/*
 * The MIT License (MIT)
 *
 * Copyright (c) 2015-2019 Erik Moqvist
 *
 * Permission is hereby granted, free of charge, to any person obtaining a copy
 * of this software and associated documentation files (the "Software"), to deal
 * in the Software without restriction, including without limitation the rights
 * to use, copy, modify, merge, publish, distribute, sublicense, and/or sell
 * copies of the Software, and to permit persons to whom the Software is
 * furnished to do so, subject to the following conditions:
 *
 * The above copyright notice and this permission notice shall be included in all
 * copies or substantial portions of the Software.
 *
 * THE SOFTWARE IS PROVIDED "AS IS", WITHOUT WARRANTY OF ANY KIND, EXPRESS OR
 * IMPLIED, INCLUDING BUT NOT LIMITED TO THE WARRANTIES OF MERCHANTABILITY,
 * FITNESS FOR A PARTICULAR PURPOSE AND NONINFRINGEMENT. IN NO EVENT SHALL THE
 * AUTHORS OR COPYRIGHT HOLDERS BE LIABLE FOR ANY CLAIM, DAMAGES OR OTHER
 * LIABILITY, WHETHER IN AN ACTION OF CONTRACT, TORT OR OTHERWISE, ARISING FROM,
 * OUT OF OR IN CONNECTION WITH THE SOFTWARE OR THE USE OR OTHER DEALINGS IN THE
 * SOFTWARE.
 */

VERSION ""

NS_ :

BS_:

BU_: UnusedNode

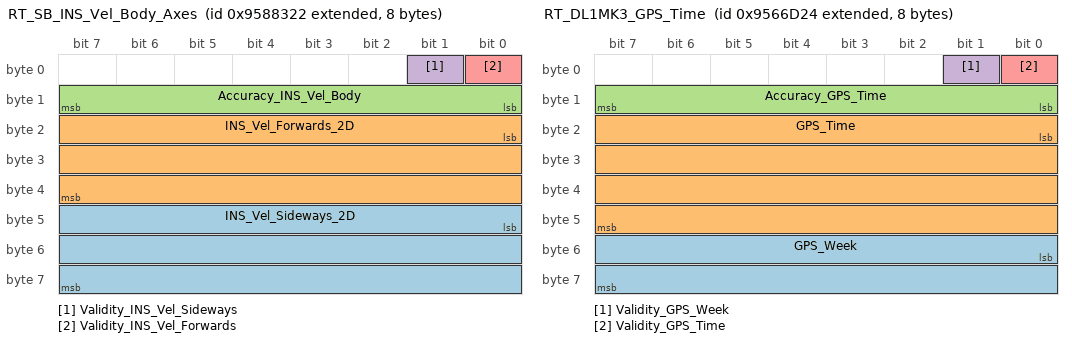
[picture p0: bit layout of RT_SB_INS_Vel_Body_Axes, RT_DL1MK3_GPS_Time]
BO_ 2304279330 RT_SB_INS_Vel_Body_Axes: 8 Vector__XXX
 SG_ INS_Vel_Sideways_2D : 40|24@1- (0.0001,0) [-838|838] "m/s" Vector__XXX
 SG_ INS_Vel_Forwards_2D : 16|24@1- (0.0001,0) [-838|838] "m/s" Vector__XXX
 SG_ Accuracy_INS_Vel_Body : 8|8@1+ (1,0) [0|255] "" Vector__XXX
 SG_ Validity_INS_Vel_Sideways : 1|1@1+ (1,0) [0|1] "" Vector__XXX
 SG_ Validity_INS_Vel_Forwards : 0|1@1+ (1,0) [0|1] "" Vector__XXX

BO_ 2303360036 RT_DL1MK3_Speed: 8 Vector__XXX
 SG_ Speed : 16|32@1- (1e-05,0) [-20000|20000] "m/s" Vector__XXX
 SG_ Accuracy_Speed : 8|8@1+ (1,0) [0|255] "" Vector__XXX
 SG_ Validity_Speed : 0|1@1+ (1,0) [0|0] "" Vector__XXX

BO_ 2304142628 RT_DL1MK3_GPS_Time: 8 Vector__XXX
 SG_ GPS_Week : 48|16@1+ (1,0) [0|65535] "" Vector__XXX
 SG_ GPS_Time : 16|32@1+ (0.001,0) [0|604800] "s" Vector__XXX
 SG_ Accuracy_GPS_Time : 8|8@1+ (1,0) [0|255] "" Vector__XXX
 SG_ Validity_GPS_Week : 1|1@1+ (1,0) [0|1] "" Vector__XXX
 SG_ Validity_GPS_Time : 0|1@1+ (1,0) [0|1] "" Vector__XXX

BO_ 2304143140 RT_DL1MK3_GPS_Pos_LLH_2: 8 Vector__XXX
 SG_ GPS_Pos_LLH_Altitude : 32|32@1- (0.001,0) [-1000|100000] "m" Vector__XXX
 SG_ GPS_Pos_LLH_Longitude : 0|32@1- (1e-07,0) [-180|180] "degrees" Vector__XXX

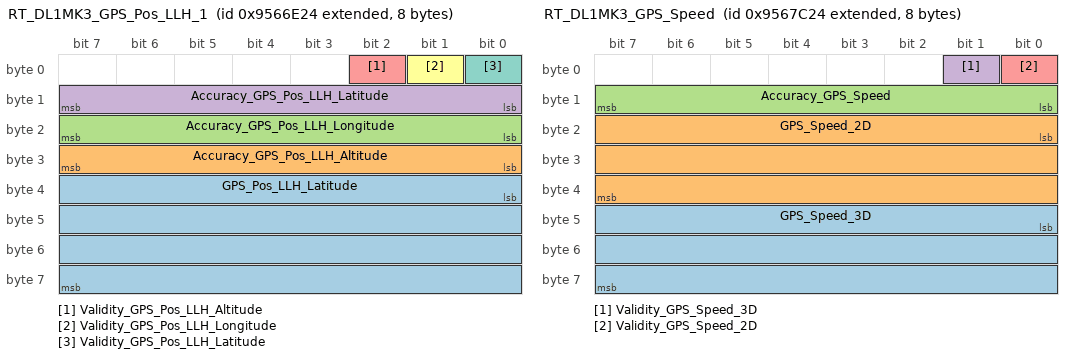
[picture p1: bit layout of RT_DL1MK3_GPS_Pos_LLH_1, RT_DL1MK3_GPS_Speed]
BO_ 2304142884 RT_DL1MK3_GPS_Pos_LLH_1: 8 Vector__XXX
 SG_ GPS_Pos_LLH_Latitude : 32|32@1- (1e-07,0) [-90|90] "degrees" Vector__XXX
 SG_ Accuracy_GPS_Pos_LLH_Altitude : 24|8@1+ (1,0) [0|255] "" Vector__XXX
 SG_ Accuracy_GPS_Pos_LLH_Longitude : 16|8@1+ (1,0) [0|255] "" Vector__XXX
 SG_ Accuracy_GPS_Pos_LLH_Latitude : 8|8@1+ (1,0) [0|255] "" Vector__XXX
 SG_ Validity_GPS_Pos_LLH_Altitude : 2|1@1+ (1,0) [0|1] "" Vector__XXX
 SG_ Validity_GPS_Pos_LLH_Longitude : 1|1@1+ (1,0) [0|1] "" Vector__XXX
 SG_ Validity_GPS_Pos_LLH_Latitude : 0|1@1+ (1,0) [0|1] "" Vector__XXX

BO_ 2304146468 RT_DL1MK3_GPS_Speed: 8 Vector__XXX
 SG_ GPS_Speed_3D : 40|24@1+ (0.0001,0) [0|1675] "m/s" Vector__XXX
 SG_ GPS_Speed_2D : 16|24@1+ (0.0001,0) [0|1675] "m/s" Vector__XXX
 SG_ Accuracy_GPS_Speed : 8|8@1+ (1,0) [0|255] "" Vector__XXX
 SG_ Validity_GPS_Speed_3D : 1|1@1+ (1,0) [0|1] "" Vector__XXX
 SG_ Validity_GPS_Speed_2D : 0|1@1+ (1,0) [0|1] "" Vector__XXX

BO_ 2304471845 RT_IRTemp_Temp_7: 2 Vector__XXX
 SG_ IR_Temperature_7 : 0|16@1- (0.1,0) [0|0] "" Vector__XXX

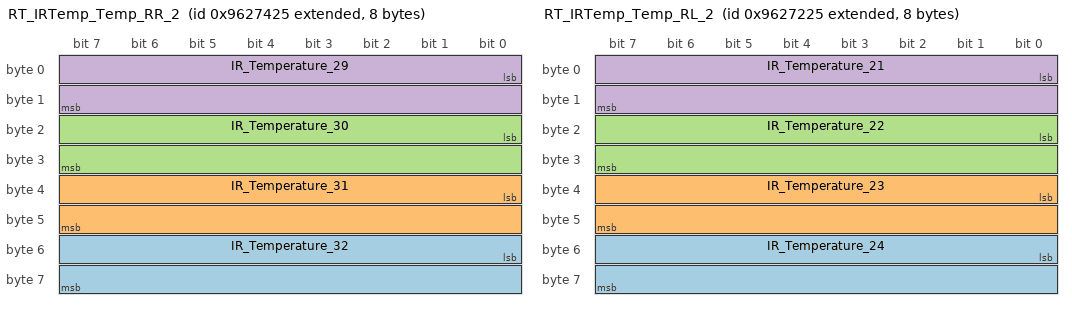
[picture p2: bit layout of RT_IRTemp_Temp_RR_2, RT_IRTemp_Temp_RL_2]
BO_ 2304930853 RT_IRTemp_Temp_RR_2: 8 Vector__XXX
 SG_ IR_Temperature_32 : 48|16@1- (0.1,0) [0|0] "" Vector__XXX
 SG_ IR_Temperature_31 : 32|16@1- (0.1,0) [0|0] "" Vector__XXX
 SG_ IR_Temperature_30 : 16|16@1- (0.1,0) [0|0] "" Vector__XXX
 SG_ IR_Temperature_29 : 0|16@1- (0.1,0) [0|0] "" Vector__XXX

BO_ 2304930341 RT_IRTemp_Temp_RL_2: 8 Vector__XXX
 SG_ IR_Temperature_24 : 48|16@1- (0.1,0) [0|0] "" Vector__XXX
 SG_ IR_Temperature_23 : 32|16@1- (0.1,0) [0|0] "" Vector__XXX
 SG_ IR_Temperature_22 : 16|16@1- (0.1,0) [0|0] "" Vector__XXX
 SG_ IR_Temperature_21 : 0|16@1- (0.1,0) [0|0] "" Vector__XXX

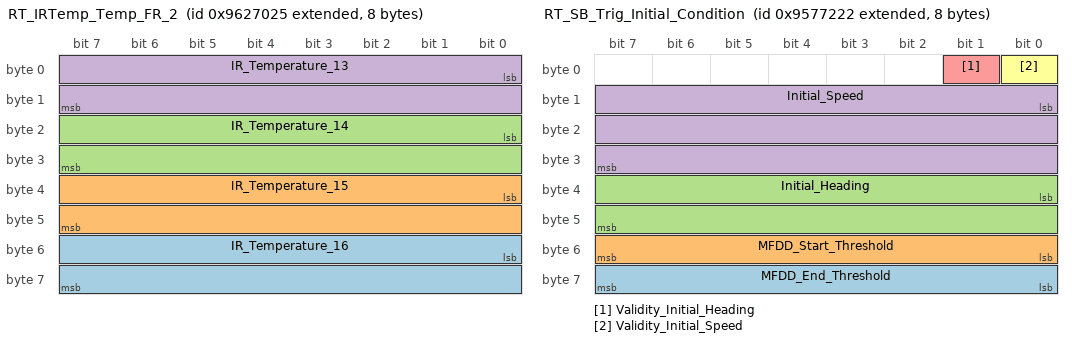
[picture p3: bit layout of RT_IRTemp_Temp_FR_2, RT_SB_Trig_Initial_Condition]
BO_ 2304929829 RT_IRTemp_Temp_FR_2: 8 Vector__XXX
 SG_ IR_Temperature_16 : 48|16@1- (0.1,0) [0|0] "" Vector__XXX
 SG_ IR_Temperature_15 : 32|16@1- (0.1,0) [0|0] "" Vector__XXX
 SG_ IR_Temperature_14 : 16|16@1- (0.1,0) [0|0] "" Vector__XXX
 SG_ IR_Temperature_13 : 0|16@1- (0.1,0) [0|0] "" Vector__XXX

BO_ 2304929317 RT_IRTemp_Temp_FL_2: 8 Vector__XXX
 SG_ IR_Temperature_8 : 48|16@1- (0.1,0) [0|0] "" Vector__XXX
 SG_ IR_Temperature_7 : 32|16@1- (0.1,0) [0|0] "" Vector__XXX
 SG_ IR_Temperature_6 : 16|16@1- (0.1,0) [0|0] "" Vector__XXX
 SG_ IR_Temperature_5 : 0|16@1- (0.1,0) [0|0] "" Vector__XXX

BO_ 2304930597 RT_IRTemp_Temp_RR_1: 8 Vector__XXX
 SG_ IR_Temperature_28 : 48|16@1- (0.1,0) [0|0] "" Vector__XXX
 SG_ IR_Temperature_27 : 32|16@1- (0.1,0) [0|0] "" Vector__XXX
 SG_ IR_Temperature_26 : 16|16@1- (0.1,0) [0|0] "" Vector__XXX
 SG_ IR_Temperature_25 : 0|16@1- (0.1,0) [0|0] "" Vector__XXX

BO_ 2304930085 RT_IRTemp_Temp_RL_1: 8 Vector__XXX
 SG_ IR_Temperature_20 : 48|16@1- (0.1,0) [0|0] "" Vector__XXX
 SG_ IR_Temperature_19 : 32|16@1- (0.1,0) [0|0] "" Vector__XXX
 SG_ IR_Temperature_18 : 16|16@1- (0.1,0) [0|0] "" Vector__XXX
 SG_ IR_Temperature_17 : 0|16@1- (0.1,0) [0|0] "" Vector__XXX

BO_ 2304929573 RT_IRTemp_Temp_FR_1: 8 Vector__XXX
 SG_ IR_Temperature_12 : 48|16@1- (0.1,0) [0|0] "" Vector__XXX
 SG_ IR_Temperature_11 : 32|16@1- (0.1,0) [0|0] "" Vector__XXX
 SG_ IR_Temperature_10 : 16|16@1- (0.1,0) [0|0] "" Vector__XXX
 SG_ IR_Temperature_9 : 0|16@1- (0.1,0) [0|0] "" Vector__XXX

BO_ 2304929061 RT_IRTemp_Temp_FL_1: 8 Vector__XXX
 SG_ IR_Temperature_4 : 48|16@1- (0.1,0) [0|0] "" Vector__XXX
 SG_ IR_Temperature_3 : 32|16@1- (0.1,0) [0|0] "" Vector__XXX
 SG_ IR_Temperature_2 : 16|16@1- (0.1,0) [0|0] "" Vector__XXX
 SG_ IR_Temperature_1 : 0|16@1- (0.1,0) [0|0] "" Vector__XXX

BO_ 2304478245 RT_IRTemp_Temp_32: 2 Vector__XXX
 SG_ IR_Temperature_32 : 0|16@1- (0.1,0) [0|0] "" Vector__XXX

BO_ 2304477989 RT_IRTemp_Temp_31: 2 Vector__XXX
 SG_ IR_Temperature_31 : 0|16@1- (0.1,0) [0|0] "" Vector__XXX

BO_ 2304477733 RT_IRTemp_Temp_30: 2 Vector__XXX
 SG_ IR_Temperature_30 : 0|16@1- (0.1,0) [0|0] "" Vector__XXX

BO_ 2304477477 RT_IRTemp_Temp_29: 2 Vector__XXX
 SG_ IR_Temperature_29 : 0|16@1- (0.1,0) [0|0] "" Vector__XXX

BO_ 2304477221 RT_IRTemp_Temp_28: 2 Vector__XXX
 SG_ IR_Temperature_28 : 0|16@1- (0.1,0) [0|0] "" Vector__XXX

BO_ 2304476965 RT_IRTemp_Temp_27: 2 Vector__XXX
 SG_ IR_Temperature_27 : 0|16@1- (0.1,0) [0|0] "" Vector__XXX

BO_ 2304476709 RT_IRTemp_Temp_26: 2 Vector__XXX
 SG_ IR_Temperature_26 : 0|16@1- (0.1,0) [0|0] "" Vector__XXX

BO_ 2304476453 RT_IRTemp_Temp_25: 2 Vector__XXX
 SG_ IR_Temperature_25 : 0|16@1- (0.1,0) [0|0] "" Vector__XXX

BO_ 2304476197 RT_IRTemp_Temp_24: 2 Vector__XXX
 SG_ IR_Temperature_24 : 0|16@1- (0.1,0) [0|0] "" Vector__XXX

BO_ 2304475685 RT_IRTemp_Temp_22: 2 Vector__XXX
 SG_ IR_Temperature_22 : 0|16@1- (0.1,0) [0|0] "" Vector__XXX

BO_ 2304475941 RT_IRTemp_Temp_23: 2 Vector__XXX
 SG_ IR_Temperature_23 : 0|16@1- (0.1,0) [0|0] "" Vector__XXX

BO_ 2304475429 RT_IRTemp_Temp_21: 2 Vector__XXX
 SG_ IR_Temperature_21 : 0|16@1- (0.1,0) [0|0] "" Vector__XXX

BO_ 2304475173 RT_IRTemp_Temp_20: 2 Vector__XXX
 SG_ IR_Temperature_20 : 0|16@1- (0.1,0) [0|0] "" Vector__XXX

BO_ 2304474917 RT_IRTemp_Temp_19: 2 Vector__XXX
 SG_ IR_Temperature_19 : 0|16@1- (0.1,0) [0|0] "" Vector__XXX

BO_ 2304474661 RT_IRTemp_Temp_18: 2 Vector__XXX
 SG_ IR_Temperature_18 : 0|16@1- (0.1,0) [0|0] "" Vector__XXX

BO_ 2304474149 RT_IRTemp_Temp_16: 2 Vector__XXX
 SG_ IR_Temperature_16 : 0|16@1- (0.1,0) [0|0] "" Vector__XXX

BO_ 2304473893 RT_IRTemp_Temp_15: 2 Vector__XXX
 SG_ IR_Temperature_15 : 0|16@1- (0.1,0) [0|0] "" Vector__XXX

BO_ 2304473637 RT_IRTemp_Temp_14: 2 Vector__XXX
 SG_ IR_Temperature_14 : 0|16@1- (0.1,0) [0|0] "" Vector__XXX

BO_ 2304473381 RT_IRTemp_Temp_13: 2 Vector__XXX
 SG_ IR_Temperature_13 : 0|16@1- (0.1,0) [0|0] "" Vector__XXX

BO_ 2304473125 RT_IRTemp_Temp_12: 2 Vector__XXX
 SG_ IR_Temperature_12 : 0|16@1- (0.1,0) [0|0] "" Vector__XXX

BO_ 2304472869 RT_IRTemp_Temp_11: 2 Vector__XXX
 SG_ IR_Temperature_11 : 0|16@1- (0.1,0) [0|0] "" Vector__XXX

BO_ 2304472613 RT_IRTemp_Temp_10: 2 Vector__XXX
 SG_ IR_Temperature_10 : 0|16@1- (0.1,0) [0|0] "" Vector__XXX

BO_ 2304472101 RT_IRTemp_Temp_8: 2 Vector__XXX
 SG_ IR_Temperature_8 : 0|16@1- (0.1,0) [0|0] "" Vector__XXX

BO_ 2304472357 RT_IRTemp_Temp_9: 2 Vector__XXX
 SG_ IR_Temperature_9 : 0|16@1- (0.1,0) [0|0] "" Vector__XXX

BO_ 2304474405 RT_IRTemp_Temp_17: 2 Vector__XXX
 SG_ IR_Temperature_17 : 0|16@1- (0.1,0) [0|0] "" Vector__XXX

BO_ 2304471589 RT_IRTemp_Temp_6: 2 Vector__XXX
 SG_ IR_Temperature_6 : 0|16@1- (0.1,0) [0|0] "" Vector__XXX

BO_ 2304471333 RT_IRTemp_Temp_5: 2 Vector__XXX
 SG_ IR_Temperature_5 : 0|16@1- (0.1,0) [0|0] "" Vector__XXX

BO_ 2304471077 RT_IRTemp_Temp_4: 2 Vector__XXX
 SG_ IR_Temperature_4 : 0|16@1- (0.1,0) [0|0] "" Vector__XXX

BO_ 2304470821 RT_IRTemp_Temp_3: 2 Vector__XXX
 SG_ IR_Temperature_3 : 0|16@1- (0.1,0) [0|0] "" Vector__XXX

BO_ 2304470565 RT_IRTemp_Temp_2: 2 Vector__XXX
 SG_ IR_Temperature_2 : 0|16@1- (0.1,0) [0|0] "" Vector__XXX

BO_ 2304470309 RT_IRTemp_Temp_1: 2 Vector__XXX
 SG_ IR_Temperature_1 : 0|16@1- (0.1,0) [0|0] "" Vector__XXX

BO_ 2304209698 RT_SB_Trig_Final_Condition: 8 Vector__XXX
 SG_ Final_Speed : 8|24@1+ (0.0001,0) [0|1675] "m/s" Vector__XXX
 SG_ Validity_Final_Speed : 0|1@1+ (1,0) [0|1] "" Vector__XXX

BO_ 2304209442 RT_SB_Trig_Initial_Condition: 8 Vector__XXX
 SG_ MFDD_End_Threshold : 56|8@1+ (1,0) [0|100] "%" Vector__XXX
 SG_ MFDD_Start_Threshold : 48|8@1+ (1,0) [0|100] "%" Vector__XXX
 SG_ Initial_Heading : 32|16@1- (0.01,0) [-180|180] "degrees" Vector__XXX
 SG_ Initial_Speed : 8|24@1+ (0.0001,0) [0|1675] "m/s" Vector__XXX
 SG_ Validity_Initial_Heading : 1|1@1+ (1,0) [0|1] "" Vector__XXX
 SG_ Validity_Initial_Speed : 0|1@1+ (1,0) [0|1] "" Vector__XXX

BO_ 2304209186 RT_SB_Trig_Direct_Dist: 8 Vector__XXX
 SG_ Path_Distance_2D : 32|32@1+ (0.001,0) [0|4294967] "m" Vector__XXX
 SG_ Direct_Distance : 0|32@1+ (0.001,0) [0|4294967] "m" Vector__XXX

BO_ 2304208930 RT_SB_Trig_Forward_Dist: 8 Vector__XXX
 SG_ Deviation_Distance : 32|32@1- (0.001,0) [-2147483.648|2147483.647] "m" Vector__XXX
 SG_ Forward_Distance : 0|32@1- (0.001,0) [-2147483.648|2147483.647] "m" Vector__XXX

BO_ 2304208674 RT_SB_Trig_Path_Dist: 8 Vector__XXX
 SG_ Path_Distance_3D : 0|32@1+ (0.001,0) [0|4294967] "m" Vector__XXX

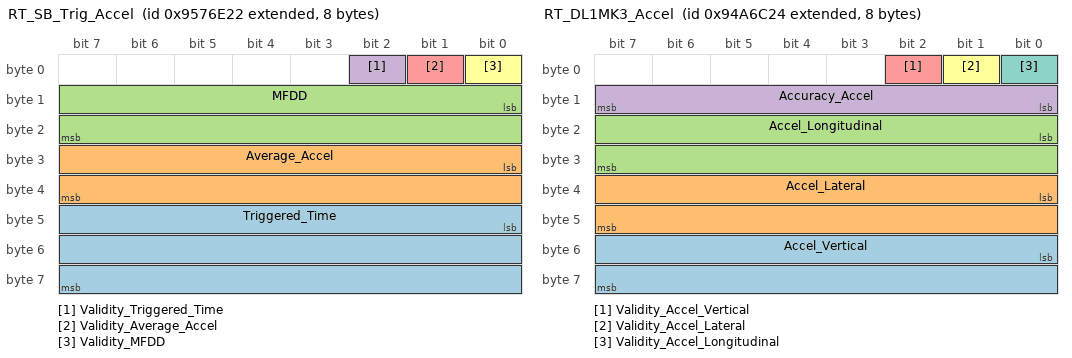
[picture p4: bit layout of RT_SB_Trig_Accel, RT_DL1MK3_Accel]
BO_ 2304208418 RT_SB_Trig_Accel: 8 Vector__XXX
 SG_ Triggered_Time : 40|24@1+ (0.01,0) [0|167772] "s" Vector__XXX
 SG_ Average_Accel : 24|16@1- (0.001,0) [-65|65] "g" Vector__XXX
 SG_ MFDD : 8|16@1- (0.001,0) [-65|65] "g" Vector__XXX
 SG_ Validity_Triggered_Time : 2|1@1+ (1,0) [0|0] "" Vector__XXX
 SG_ Validity_Average_Accel : 1|1@1+ (1,0) [0|0] "" Vector__XXX
 SG_ Validity_MFDD : 0|1@1+ (1,0) [0|0] "" Vector__XXX

BO_ 2304800804 RT_DL1MK3_Measure_Time_12: 3 Vector__XXX
 SG_ Measured_Time_12 : 0|24@1+ (1,0) [0|0] "" Vector__XXX

BO_ 2304800548 RT_DL1MK3_Measure_Time_11: 3 Vector__XXX
 SG_ Measured_Time_11 : 0|24@1+ (1,0) [0|0] "" Vector__XXX

BO_ 2304800292 RT_DL1MK3_Measure_Time_10: 3 Vector__XXX
 SG_ Measured_Time_10 : 0|24@1+ (1,0) [0|0] "" Vector__XXX

BO_ 2304800036 RT_DL1MK3_Measure_Time_9: 3 Vector__XXX
 SG_ Measured_Time_9 : 0|24@1+ (1,0) [0|0] "" Vector__XXX

BO_ 2304799780 RT_DL1MK3_Measure_Time_8: 3 Vector__XXX
 SG_ Measured_Time_8 : 0|24@1+ (1,0) [0|0] "" Vector__XXX

BO_ 2304799524 RT_DL1MK3_Measure_Time_7: 3 Vector__XXX
 SG_ Measured_Time_7 : 0|24@1+ (1,0) [0|0] "" Vector__XXX

BO_ 2304799268 RT_DL1MK3_Measure_Time_6: 3 Vector__XXX
 SG_ Measured_Time_6 : 0|24@1+ (1,0) [0|0] "" Vector__XXX

BO_ 2304799012 RT_DL1MK3_Measure_Time_5: 3 Vector__XXX
 SG_ Measured_Time_5 : 0|24@1+ (1,0) [0|0] "" Vector__XXX

BO_ 2304798756 RT_DL1MK3_Measure_Time_4: 3 Vector__XXX
 SG_ Measured_Time_4 : 0|24@1+ (1,0) [0|0] "" Vector__XXX

BO_ 2304798500 RT_DL1MK3_Measure_Time_3: 3 Vector__XXX
 SG_ Measured_Time_3 : 0|24@1+ (1,0) [0|0] "" Vector__XXX

BO_ 2304798244 RT_DL1MK3_Measure_Time_2: 3 Vector__XXX
 SG_ Measured_Time_2 : 0|24@1+ (1,0) [0|0] "" Vector__XXX

BO_ 2304797988 RT_DL1MK3_Measure_Time_1: 3 Vector__XXX
 SG_ Measured_Time_1 : 0|24@1+ (1,0) [0|0] "" Vector__XXX

BO_ 2304735268 RT_DL1MK3_RPM: 2 Vector__XXX
 SG_ RPM : 0|16@1+ (1,0) [0|0] "" Vector__XXX

BO_ 2304735012 RT_DL1MK3_Freq_4: 2 Vector__XXX
 SG_ Frequency_4 : 0|16@1+ (0.1,0) [0|0] "" Vector__XXX

BO_ 2304734756 RT_DL1MK3_Freq_3: 2 Vector__XXX
 SG_ Frequency_3 : 0|16@1+ (0.1,0) [0|0] "" Vector__XXX

BO_ 2304734500 RT_DL1MK3_Freq_2: 2 Vector__XXX
 SG_ Frequency_2 : 0|16@1+ (0.1,0) [0|0] "" Vector__XXX

BO_ 2304864036 RT_DL1MK3_Misc_3: 2 Vector__XXX
 SG_ Misc_3 : 0|16@1+ (0.001,0) [0|0] "" Vector__XXX

BO_ 2304863780 RT_DL1MK3_Misc_2: 2 Vector__XXX
 SG_ Misc_2 : 0|16@1+ (0.001,0) [0|0] "" Vector__XXX

BO_ 2304863524 RT_DL1MK3_Misc_1: 2 Vector__XXX
 SG_ Misc_1 : 0|16@1+ (0.001,0) [0|0] "" Vector__XXX

BO_ 2304674596 RT_DL1MK3_Aux_31: 2 Vector__XXX
 SG_ AUX_31 : 0|16@1+ (0.1,0) [0|0] "" Vector__XXX

BO_ 2304674340 RT_DL1MK3_Aux_30: 2 Vector__XXX
 SG_ AUX_30 : 0|16@1+ (0.1,0) [0|0] "" Vector__XXX

BO_ 2304674084 RT_DL1MK3_Aux_29: 2 Vector__XXX
 SG_ AUX_29 : 0|16@1+ (0.1,0) [0|0] "" Vector__XXX

BO_ 2304673828 RT_DL1MK3_Aux_28: 2 Vector__XXX
 SG_ AUX_28 : 0|16@1+ (0.1,0) [0|0] "" Vector__XXX

BO_ 2304673572 RT_DL1MK3_Aux_27: 2 Vector__XXX
 SG_ AUX_27 : 0|16@1+ (0.1,0) [0|0] "" Vector__XXX

BO_ 2304673316 RT_DL1MK3_Aux_26: 2 Vector__XXX
 SG_ AUX_26 : 0|16@1+ (0.1,0) [0|0] "" Vector__XXX

BO_ 2304673060 RT_DL1MK3_Aux_25: 2 Vector__XXX
 SG_ AUX_25 : 0|16@1+ (0.1,0) [0|0] "" Vector__XXX

BO_ 2304672804 RT_DL1MK3_Aux_24: 2 Vector__XXX
 SG_ AUX_24 : 0|16@1+ (0.1,0) [0|0] "" Vector__XXX

BO_ 2304672548 RT_DL1MK3_Aux_23: 2 Vector__XXX
 SG_ AUX_23 : 0|16@1+ (0.1,0) [0|0] "" Vector__XXX

BO_ 2304672292 RT_DL1MK3_Aux_22: 2 Vector__XXX
 SG_ AUX_22 : 0|16@1+ (10,0) [0|0] "" Vector__XXX

BO_ 2304672036 RT_DL1MK3_Aux_21: 2 Vector__XXX
 SG_ AUX_21 : 0|16@1+ (0.1,0) [0|0] "" Vector__XXX

BO_ 2304671780 RT_DL1MK3_Aux_20: 2 Vector__XXX
 SG_ AUX_20 : 0|16@1+ (0.1,0) [0|0] "" Vector__XXX

BO_ 2304671524 RT_DL1MK3_Aux_19: 2 Vector__XXX
 SG_ AUX_19 : 0|16@1+ (0.1,0) [0|0] "" Vector__XXX

BO_ 2304671268 RT_DL1MK3_Aux_18: 2 Vector__XXX
 SG_ AUX_18 : 0|16@1+ (0.1,0) [0|0] "" Vector__XXX

BO_ 2304671012 RT_DL1MK3_Aux_17: 2 Vector__XXX
 SG_ AUX_17 : 0|16@1+ (0.1,0) [0|0] "" Vector__XXX

BO_ 2304670756 RT_DL1MK3_Aux_16: 2 Vector__XXX
 SG_ AUX_16 : 0|16@1+ (0.1,0) [0|0] "" Vector__XXX

BO_ 2304670500 RT_DL1MK3_Aux_15: 2 Vector__XXX
 SG_ AUX_15 : 0|16@1+ (0.1,0) [0|0] "" Vector__XXX

BO_ 2304670244 RT_DL1MK3_Aux_14: 2 Vector__XXX
 SG_ AUX_14 : 0|16@1+ (0.1,0) [0|0] "" Vector__XXX

BO_ 2304669988 RT_DL1MK3_Aux_13: 2 Vector__XXX
 SG_ AUX_13 : 0|16@1+ (0.1,0) [0|0] "" Vector__XXX

BO_ 2304669732 RT_DL1MK3_Aux_12: 2 Vector__XXX
 SG_ AUX_12 : 0|16@1+ (0.1,0) [0|0] "" Vector__XXX

BO_ 2304669476 RT_DL1MK3_Aux_11: 2 Vector__XXX
 SG_ AUX_11 : 0|16@1+ (0.1,0) [0|0] "" Vector__XXX

BO_ 2304668964 RT_DL1MK3_Aux_9: 2 Vector__XXX
 SG_ AUX_9 : 0|16@1+ (0.1,0) [0|0] "" Vector__XXX

BO_ 2304669220 RT_DL1MK3_Aux_10: 2 Vector__XXX
 SG_ AUX_10 : 0|16@1+ (0.1,0) [0|0] "" Vector__XXX

BO_ 2304668708 RT_DL1MK3_Aux_8: 2 Vector__XXX
 SG_ AUX_8 : 0|16@1+ (0.1,0) [0|0] "" Vector__XXX

BO_ 2304668452 RT_DL1MK3_Aux_7: 2 Vector__XXX
 SG_ AUX_7 : 0|16@1+ (0.1,0) [0|0] "" Vector__XXX

BO_ 2304668196 RT_DL1MK3_Aux_6: 2 Vector__XXX
 SG_ AUX_6 : 0|16@1+ (0.1,0) [0|0] "" Vector__XXX

BO_ 2304667940 RT_DL1MK3_Aux_5: 2 Vector__XXX
 SG_ AUX_5 : 0|16@1+ (0.1,0) [0|0] "" Vector__XXX

BO_ 2304667684 RT_DL1MK3_Aux_4: 2 Vector__XXX
 SG_ AUX_4 : 0|16@1+ (0.1,0) [0|0] "" Vector__XXX

BO_ 2304667428 RT_DL1MK3_Aux_3: 2 Vector__XXX
 SG_ AUX_3 : 0|16@1+ (0.1,0) [0|0] "" Vector__XXX

BO_ 2304667172 RT_DL1MK3_Aux_2: 2 Vector__XXX
 SG_ AUX_2 : 0|16@1+ (0.1,0) [0|0] "" Vector__XXX

BO_ 2304666916 RT_DL1MK3_Aux_1: 2 Vector__XXX
 SG_ AUX_1 : 0|16@1+ (0.1,0) [0|0] "" Vector__XXX

BO_ 2304405796 RT_DL1MK3_Pressure_5: 3 Vector__XXX
 SG_ Pressure_5 : 0|24@1+ (0.1,0) [0|0] "" Vector__XXX

BO_ 2304405540 RT_DL1MK3_Pressure_4: 3 Vector__XXX
 SG_ Pressure_4 : 0|24@1+ (0.1,0) [0|0] "" Vector__XXX

BO_ 2304405284 RT_DL1MK3_Pressure_3: 3 Vector__XXX
 SG_ Pressure_3 : 0|24@1+ (0.1,0) [0|0] "" Vector__XXX

BO_ 2304405028 RT_DL1MK3_Pressure_2: 3 Vector__XXX
 SG_ Pressure_2 : 0|24@1+ (0.1,0) [0|0] "" Vector__XXX

BO_ 2304404772 RT_DL1MK3_Pressure_1: 3 Vector__XXX
 SG_ Pressure_1 : 0|24@1+ (0.1,0) [0|0] "" Vector__XXX

BO_ 2304536356 RT_DL1MK3_Angle_3: 2 Vector__XXX
 SG_ Angle_3 : 0|16@1- (0.1,0) [0|0] "" Vector__XXX

BO_ 2304536100 RT_DL1MK3_Angle_2: 2 Vector__XXX
 SG_ Angle_2 : 0|16@1- (0.1,0) [0|0] "" Vector__XXX

BO_ 2304535844 RT_DL1MK3_Angle_1: 2 Vector__XXX
 SG_ Angle_1 : 0|16@1- (0.1,0) [0|0] "" Vector__XXX

BO_ 2304476452 RT_DL1MK3_Temp_25: 2 Vector__XXX
 SG_ Temperature_25 : 0|16@1- (0.1,0) [0|0] "" Vector__XXX

BO_ 2304476196 RT_DL1MK3_Temp_24: 2 Vector__XXX
 SG_ Temperature_24 : 0|16@1- (0.1,0) [0|0] "" Vector__XXX

BO_ 2304475940 RT_DL1MK3_Temp_23: 2 Vector__XXX
 SG_ Temperature_23 : 0|16@1- (0.1,0) [0|0] "" Vector__XXX

BO_ 2304475684 RT_DL1MK3_Temp_22: 2 Vector__XXX
 SG_ Temperature_22 : 0|16@1- (0.1,0) [0|0] "" Vector__XXX

BO_ 2304475428 RT_DL1MK3_Temp_21: 2 Vector__XXX
 SG_ Temperature_21 : 0|16@1- (0.1,0) [0|0] "" Vector__XXX

BO_ 2304475172 RT_DL1MK3_Temp_20: 2 Vector__XXX
 SG_ Temperature_20 : 0|16@1- (0.1,0) [0|0] "" Vector__XXX

BO_ 2304474916 RT_DL1MK3_Temp_19: 2 Vector__XXX
 SG_ Temperature_19 : 0|16@1- (0.1,0) [0|0] "" Vector__XXX

BO_ 2304474660 RT_DL1MK3_Temp_18: 2 Vector__XXX
 SG_ Temperature_18 : 0|16@1- (0.1,0) [0|0] "" Vector__XXX

BO_ 2304474404 RT_DL1MK3_Temp_17: 2 Vector__XXX
 SG_ Temperature_17 : 0|16@1- (0.1,0) [0|0] "" Vector__XXX

BO_ 2304474148 RT_DL1MK3_Temp_16: 2 Vector__XXX
 SG_ Temperature_16 : 0|16@1- (0.1,0) [0|0] "" Vector__XXX

BO_ 2304473892 RT_DL1MK3_Temp_15: 2 Vector__XXX
 SG_ Temperature_15 : 0|16@1- (0.1,0) [0|0] "" Vector__XXX

BO_ 2304473636 RT_DL1MK3_Temp_14: 2 Vector__XXX
 SG_ Temperature_14 : 0|16@1- (0.1,0) [0|0] "" Vector__XXX

BO_ 2304473380 RT_DL1MK3_Temp_13: 2 Vector__XXX
 SG_ Temperature_13 : 0|16@1- (0.1,0) [0|0] "" Vector__XXX

BO_ 2304473124 RT_DL1MK3_Temp_12: 2 Vector__XXX
 SG_ Temperature_12 : 0|16@1- (0.1,0) [0|0] "" Vector__XXX

BO_ 2304472868 RT_DL1MK3_Temp_11: 2 Vector__XXX
 SG_ Temperature_11 : 0|16@1- (0.1,0) [0|0] "" Vector__XXX

BO_ 2304472612 RT_DL1MK3_Temp_10: 2 Vector__XXX
 SG_ Temperature_10 : 0|16@1- (0.1,0) [0|0] "" Vector__XXX

BO_ 2304472356 RT_DL1MK3_Temp_9: 2 Vector__XXX
 SG_ Temperature_9 : 0|16@1- (0.1,0) [0|0] "" Vector__XXX

BO_ 2304472100 RT_DL1MK3_Temp_8: 2 Vector__XXX
 SG_ Temperature_8 : 0|16@1- (0.1,0) [0|0] "" Vector__XXX

BO_ 2304471844 RT_DL1MK3_Temp_7: 2 Vector__XXX
 SG_ Temperature_7 : 0|16@1- (0.1,0) [0|0] "" Vector__XXX

BO_ 2304471588 RT_DL1MK3_Temp_6: 2 Vector__XXX
 SG_ Temperature_6 : 0|16@1- (0.1,0) [0|0] "" Vector__XXX

BO_ 2304471332 RT_DL1MK3_Temp_5: 2 Vector__XXX
 SG_ Temperature_5 : 0|16@1- (0.1,0) [0|0] "" Vector__XXX

BO_ 2304471076 RT_DL1MK3_Temp_4: 2 Vector__XXX
 SG_ Temperature_4 : 0|16@1- (0.1,0) [0|0] "" Vector__XXX

BO_ 2304470820 RT_DL1MK3_Temp_3: 2 Vector__XXX
 SG_ Temperature_3 : 0|16@1- (0.1,0) [0|0] "" Vector__XXX

BO_ 2304470564 RT_DL1MK3_Temp_2: 2 Vector__XXX
 SG_ Temperature_2 : 0|16@1- (0.1,0) [0|0] "" Vector__XXX

BO_ 2304470308 RT_DL1MK3_Temp_1: 2 Vector__XXX
 SG_ Temperature_1 : 0|16@1- (0.1,0) [0|0] "" Vector__XXX

BO_ 2303494948 RT_DL1MK3_Analog_32: 2 Vector__XXX
 SG_ Analog_32 : 7|16@0+ (0.001,0) [0|0] "" Vector__XXX

BO_ 2303494692 RT_DL1MK3_Analog_31: 2 Vector__XXX
 SG_ Analog_31 : 7|16@0+ (0.001,0) [0|0] "" Vector__XXX

BO_ 2303494436 RT_DL1MK3_Analog_30: 2 Vector__XXX
 SG_ Analog_30 : 7|16@0+ (0.001,0) [0|0] "" Vector__XXX

BO_ 2303494180 RT_DL1MK3_Analog_29: 2 Vector__XXX
 SG_ Analog_29 : 7|16@0+ (0.001,0) [0|0] "" Vector__XXX

BO_ 2303493924 RT_DL1MK3_Analog_28: 2 Vector__XXX
 SG_ Analog_28 : 7|16@0+ (0.001,0) [0|0] "" Vector__XXX

BO_ 2303493668 RT_DL1MK3_Analog_27: 2 Vector__XXX
 SG_ Analog_27 : 7|16@0+ (0.001,0) [0|0] "" Vector__XXX

BO_ 2303493412 RT_DL1MK3_Analog_26: 2 Vector__XXX
 SG_ Analog_26 : 7|16@0+ (0.001,0) [0|0] "" Vector__XXX

BO_ 2303493156 RT_DL1MK3_Analog_25: 2 Vector__XXX
 SG_ Analog_25 : 7|16@0+ (0.001,0) [0|0] "" Vector__XXX

BO_ 2303490596 RT_DL1MK3_Analog_15: 2 Vector__XXX
 SG_ Analog_15 : 7|16@0+ (0.001,0) [0|0] "" Vector__XXX

BO_ 2303490340 RT_DL1MK3_Analog_14: 2 Vector__XXX
 SG_ Analog_14 : 7|16@0+ (0.001,0) [0|0] "" Vector__XXX

BO_ 2303491108 RT_DL1MK3_Analog_17: 2 Vector__XXX
 SG_ Analog_17 : 7|16@0+ (0.001,0) [0|0] "" Vector__XXX

BO_ 2303492900 RT_DL1MK3_Analog_24: 2 Vector__XXX
 SG_ Analog_24 : 7|16@0+ (0.001,0) [0|0] "" Vector__XXX

BO_ 2303492644 RT_DL1MK3_Analog_23: 2 Vector__XXX
 SG_ Analog_23 : 7|16@0+ (0.001,0) [0|0] "" Vector__XXX

BO_ 2303492388 RT_DL1MK3_Analog_22: 2 Vector__XXX
 SG_ Analog_22 : 7|16@0+ (0.001,0) [0|0] "" Vector__XXX

BO_ 2303492132 RT_DL1MK3_Analog_21: 2 Vector__XXX
 SG_ Analog_21 : 7|16@0+ (0.001,0) [0|0] "" Vector__XXX

BO_ 2303491876 RT_DL1MK3_Analog_20: 2 Vector__XXX
 SG_ Analog_20 : 7|16@0+ (0.001,0) [0|0] "" Vector__XXX

BO_ 2303491620 RT_DL1MK3_Analog_19: 2 Vector__XXX
 SG_ Analog_19 : 7|16@0+ (0.001,0) [0|0] "" Vector__XXX

BO_ 2303490852 RT_DL1MK3_Analog_16: 2 Vector__XXX
 SG_ Analog_16 : 7|16@0+ (0.001,0) [0|0] "" Vector__XXX

BO_ 2303491364 RT_DL1MK3_Analog_18: 2 Vector__XXX
 SG_ Analog_18 : 7|16@0+ (0.001,0) [0|0] "" Vector__XXX

BO_ 2303489828 RT_DL1MK3_Analog_12: 2 Vector__XXX
 SG_ Analog_12 : 7|16@0+ (0.001,0) [0|0] "" Vector__XXX

BO_ 2303489572 RT_DL1MK3_Analog_11: 2 Vector__XXX
 SG_ Analog_11 : 7|16@0+ (0.001,0) [0|0] "" Vector__XXX

BO_ 2303489316 RT_DL1MK3_Analog_10: 2 Vector__XXX
 SG_ Analog_10 : 7|16@0+ (0.001,0) [0|0] "" Vector__XXX

BO_ 2303489060 RT_DL1MK3_Analog_9: 2 Vector__XXX
 SG_ Analog_9 : 7|16@0+ (0.001,0) [0|0] "" Vector__XXX

BO_ 2303488804 RT_DL1MK3_Analog_8: 2 Vector__XXX
 SG_ Analog_8 : 7|16@0+ (0.001,0) [0|0] "" Vector__XXX

BO_ 2303488548 RT_DL1MK3_Analog_7: 2 Vector__XXX
 SG_ Analog_7 : 7|16@0+ (0.001,0) [0|0] "" Vector__XXX

BO_ 2303488292 RT_DL1MK3_Analog_6: 2 Vector__XXX
 SG_ Analog_6 : 7|16@0+ (0.001,0) [0|0] "" Vector__XXX

BO_ 2303488036 RT_DL1MK3_Analog_5: 2 Vector__XXX
 SG_ Analog_5 : 7|16@0+ (0.001,0) [0|0] "" Vector__XXX

BO_ 2303487780 RT_DL1MK3_Analog_4: 2 Vector__XXX
 SG_ Analog_4 : 7|16@0+ (0.001,0) [0|0] "" Vector__XXX

BO_ 2303487524 RT_DL1MK3_Analog_3: 2 Vector__XXX
 SG_ Analog_3 : 7|16@0+ (0.001,0) [0|0] "" Vector__XXX

BO_ 2303487268 RT_DL1MK3_Analog_2: 2 Vector__XXX
 SG_ Analog_2 : 7|16@0+ (0.001,0) [0|0] "" Vector__XXX

BO_ 2303487012 RT_DL1MK3_Analog_1: 2 Vector__XXX
 SG_ Analog_1 : 7|16@0+ (0.001,0) [0|0] "" Vector__XXX

BO_ 2303355940 RT_DL1MK3_Accel: 8 Vector__XXX
 SG_ Accel_Vertical : 48|16@1- (0.001,0) [-65|65] "g" Vector__XXX
 SG_ Accel_Lateral : 32|16@1- (0.001,0) [-65|65] "g" Vector__XXX
 SG_ Accel_Longitudinal : 16|16@1- (0.001,0) [-65|65] "g" Vector__XXX
 SG_ Accuracy_Accel : 8|8@1+ (1,0) [0|255] "" Vector__XXX
 SG_ Validity_Accel_Vertical : 2|1@1+ (1,0) [0|0] "" Vector__XXX
 SG_ Validity_Accel_Lateral : 1|1@1+ (1,0) [0|0] "" Vector__XXX
 SG_ Validity_Accel_Longitudinal : 0|1@1+ (1,0) [0|0] "" Vector__XXX

BO_ 2304351778 RT_SB_INS_Vpt_4_Vel_NED_2: 8 Vector__XXX
 SG_ Virtual_4_Slip : 48|16@1- (0.01,0) [-180|180] "degrees" Vector__XXX
 SG_ Virtual_4_Heading : 32|16@1- (0.01,0) [-180|180] "degrees" Vector__XXX
 SG_ Virtual_4_Vel_NED_D : 0|24@1- (0.0001,0) [-838|838] "m/s" Vector__XXX

BO_ 2304351522 RT_SB_INS_Vpt_4_Vel_NED_1: 8 Vector__XXX
 SG_ Virtual_4_Vel_NED_E : 32|24@1- (0.0001,0) [-838|838] "m/s" Vector__XXX
 SG_ Virtual_4_Vel_NED_N : 0|24@1- (0.0001,0) [-838|838] "m/s" Vector__XXX

BO_ 2304351266 RT_SB_INS_Vpt_4_Offset: 8 Vector__XXX
 SG_ Virtual_4_Offset_Z : 32|16@1- (0.001,0) [-32.768|32.767] "m" Vector__XXX
 SG_ Virtual_4_Offset_Y : 16|16@1- (0.001,0) [-32.768|32.767] "m" Vector__XXX
 SG_ Virtual_4_Offset_X : 0|16@1- (0.001,0) [-32.768|32.767] "m" Vector__XXX

BO_ 2304347682 RT_SB_INS_Vpt_3_Vel_NED_2: 8 Vector__XXX
 SG_ Virtual_3_Slip : 48|16@1- (0.01,0) [-180|180] "degrees" Vector__XXX
 SG_ Virtual_3_Heading : 32|16@1- (0.01,0) [-180|180] "degrees" Vector__XXX
 SG_ Virtual_3_Vel_NED_D : 0|24@1- (0.0001,0) [-838|838] "m/s" Vector__XXX

BO_ 2304347426 RT_SB_INS_Vpt_3_Vel_NED_1: 8 Vector__XXX
 SG_ Virtual_3_Vel_NED_E : 32|24@1- (0.0001,0) [-838|838] "m/s" Vector__XXX
 SG_ Virtual_3_Vel_NED_N : 0|24@1- (0.0001,0) [-838|838] "m/s" Vector__XXX

BO_ 2304347170 RT_SB_INS_Vpt_3_Offset: 8 Vector__XXX
 SG_ Virtual_3_Offset_Z : 32|16@1- (0.001,0) [-32.768|32.767] "m" Vector__XXX
 SG_ Virtual_3_Offset_Y : 16|16@1- (0.001,0) [-32.768|32.767] "m" Vector__XXX
 SG_ Virtual_3_Offset_X : 0|16@1- (0.001,0) [-32.768|32.767] "m" Vector__XXX

BO_ 2304343586 RT_SB_INS_Vpt_2_Vel_NED_2: 8 Vector__XXX
 SG_ Virtual_2_Slip : 48|16@1- (0.01,0) [-180|180] "degrees" Vector__XXX
 SG_ Virtual_2_Heading : 32|16@1- (0.01,0) [-180|180] "degrees" Vector__XXX
 SG_ Virtual_2_Vel_NED_D : 0|24@1- (0.0001,0) [-838|838] "m/s" Vector__XXX

BO_ 2304343330 RT_SB_INS_Vpt_2_Vel_NED_1: 8 Vector__XXX
 SG_ Virtual_2_Vel_NED_E : 32|24@1- (0.0001,0) [-838|838] "m/s" Vector__XXX
 SG_ Virtual_2_Vel_NED_N : 0|24@1- (0.0001,0) [-838|838] "m/s" Vector__XXX

BO_ 2304343074 RT_SB_INS_Vpt_2_Offset: 8 Vector__XXX
 SG_ Virtual_2_Offset_Z : 32|16@1- (0.001,0) [-32.768|32.767] "m" Vector__XXX
 SG_ Virtual_2_Offset_Y : 16|16@1- (0.001,0) [-32.768|32.767] "m" Vector__XXX
 SG_ Virtual_2_Offset_X : 0|16@1- (0.001,0) [-32.768|32.767] "m" Vector__XXX

BO_ 2304339490 RT_SB_INS_Vpt_1_Vel_NED_2: 8 Vector__XXX
 SG_ Virtual_1_Slip : 48|16@1- (0.01,0) [-180|180] "degrees" Vector__XXX
 SG_ Virtual_1_Heading : 32|16@1- (0.01,0) [-180|180] "degrees" Vector__XXX
 SG_ Virtual_1_Vel_NED_D : 0|24@1- (0.0001,0) [-838|838] "m/s" Vector__XXX

BO_ 2304339234 RT_SB_INS_Vpt_1_Vel_NED_1: 8 Vector__XXX
 SG_ Virtual_1_Vel_NED_E : 32|24@1- (0.0001,0) [-838|838] "m/s" Vector__XXX
 SG_ Virtual_1_Vel_NED_N : 0|24@1- (0.0001,0) [-838|838] "m/s" Vector__XXX

BO_ 2304338978 RT_SB_INS_Vpt_1_Offset: 8 Vector__XXX
 SG_ Virtual_1_Offset_Z : 32|16@1- (0.001,0) [-32.768|32.767] "m" Vector__XXX
 SG_ Virtual_1_Offset_Y : 16|16@1- (0.001,0) [-32.768|32.767] "m" Vector__XXX
 SG_ Virtual_1_Offset_X : 0|16@1- (0.001,0) [-32.768|32.767] "m" Vector__XXX

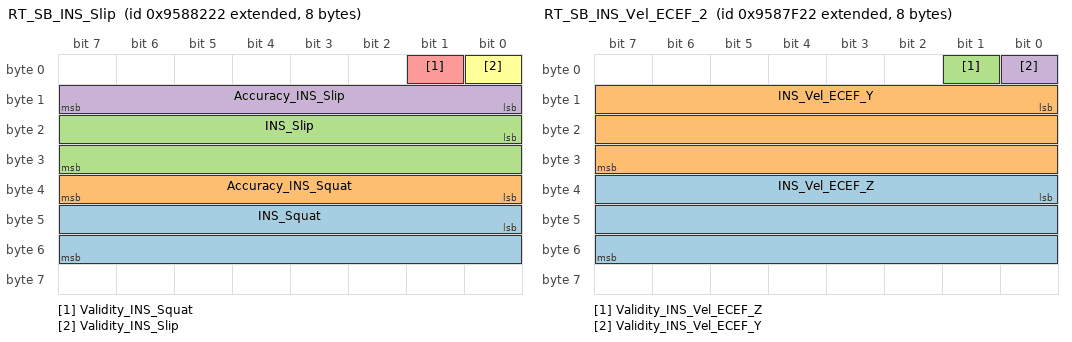
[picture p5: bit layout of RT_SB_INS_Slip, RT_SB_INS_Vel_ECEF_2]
BO_ 2304279074 RT_SB_INS_Slip: 8 Vector__XXX
 SG_ INS_Squat : 40|16@1- (0.01,0) [-360|360] "degrees" Vector__XXX
 SG_ Accuracy_INS_Squat : 32|8@1+ (1,0) [0|255] "" Vector__XXX
 SG_ INS_Slip : 16|16@1- (0.01,0) [-360|360] "degrees" Vector__XXX
 SG_ Accuracy_INS_Slip : 8|8@1+ (1,0) [0|255] "" Vector__XXX
 SG_ Validity_INS_Squat : 1|1@1+ (1,0) [0|1] "" Vector__XXX
 SG_ Validity_INS_Slip : 0|1@1+ (1,0) [0|1] "" Vector__XXX

BO_ 2304278306 RT_SB_INS_Vel_ECEF_2: 8 Vector__XXX
 SG_ INS_Vel_ECEF_Z : 32|24@1- (0.0001,0) [-838|838] "m/s" Vector__XXX
 SG_ INS_Vel_ECEF_Y : 8|24@1- (0.0001,0) [-838|838] "m/s" Vector__XXX
 SG_ Validity_INS_Vel_ECEF_Z : 1|1@1+ (1,0) [0|1] "" Vector__XXX
 SG_ Validity_INS_Vel_ECEF_Y : 0|1@1+ (1,0) [0|1] "" Vector__XXX

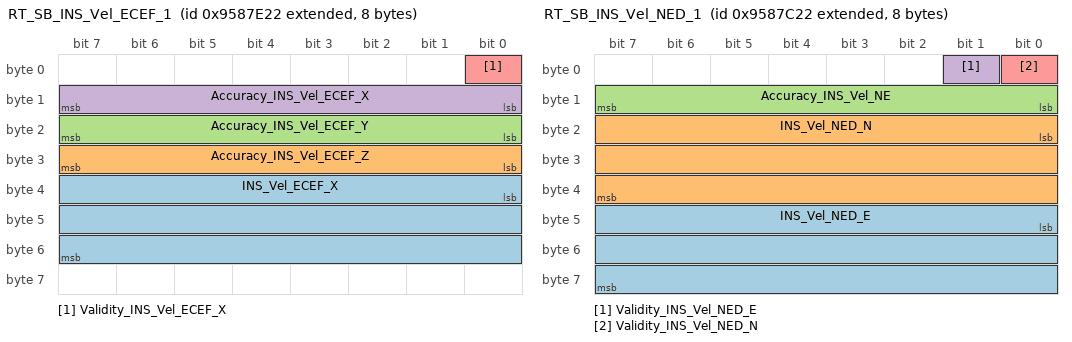
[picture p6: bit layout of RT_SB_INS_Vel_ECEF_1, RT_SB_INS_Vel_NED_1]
BO_ 2304278050 RT_SB_INS_Vel_ECEF_1: 8 Vector__XXX
 SG_ INS_Vel_ECEF_X : 32|24@1- (0.0001,0) [-838|838] "m/s" Vector__XXX
 SG_ Accuracy_INS_Vel_ECEF_Z : 24|8@1+ (1,0) [0|255] "" Vector__XXX
 SG_ Accuracy_INS_Vel_ECEF_Y : 16|8@1+ (1,0) [0|255] "" Vector__XXX
 SG_ Accuracy_INS_Vel_ECEF_X : 8|8@1+ (1,0) [0|255] "" Vector__XXX
 SG_ Validity_INS_Vel_ECEF_X : 0|1@1+ (1,0) [0|1] "" Vector__XXX

BO_ 2304277794 RT_SB_INS_Vel_NED_2: 8 Vector__XXX
 SG_ INS_Vel_NED_D : 16|24@1- (0.0001,0) [-838|838] "m/s" Vector__XXX
 SG_ Accuracy_INS_Vel_D : 8|8@1+ (1,0) [0|255] "" Vector__XXX
 SG_ Validity_INS_Vel_NED_D : 0|1@1+ (1,0) [0|1] "" Vector__XXX

BO_ 2304277538 RT_SB_INS_Vel_NED_1: 8 Vector__XXX
 SG_ INS_Vel_NED_E : 40|24@1- (0.0001,0) [-838|838] "m/s" Vector__XXX
 SG_ INS_Vel_NED_N : 16|24@1- (0.0001,0) [-838|838] "m/s" Vector__XXX
 SG_ Accuracy_INS_Vel_NE : 8|8@1+ (1,0) [0|255] "" Vector__XXX
 SG_ Validity_INS_Vel_NED_E : 1|1@1+ (1,0) [0|1] "" Vector__XXX
 SG_ Validity_INS_Vel_NED_N : 0|1@1+ (1,0) [0|1] "" Vector__XXX

BO_ 2304274722 RT_SB_INS_Pos_ECEF_2: 8 Vector__XXX
 SG_ INS_Pos_ECEF_Z : 32|32@1- (0.01,0) [-10000000|10000000] "m" Vector__XXX
 SG_ INS_Pos_ECEF_Y : 0|32@1- (0.01,0) [-10000000|10000000] "m" Vector__XXX

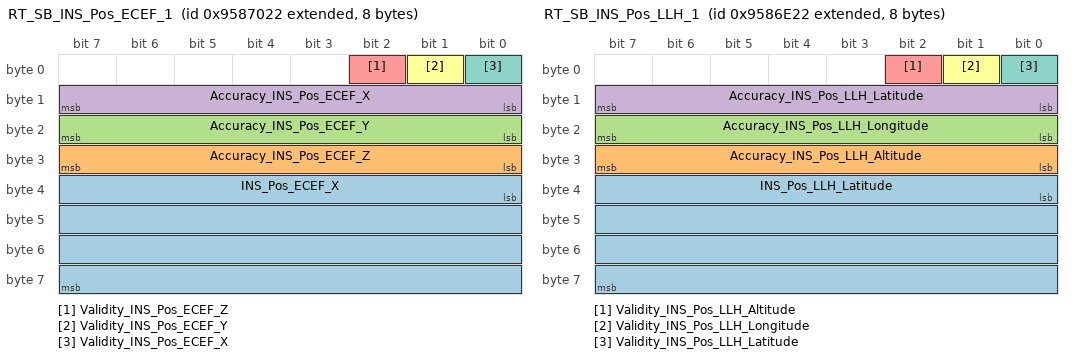
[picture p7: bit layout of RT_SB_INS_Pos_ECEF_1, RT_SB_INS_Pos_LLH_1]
BO_ 2304274466 RT_SB_INS_Pos_ECEF_1: 8 Vector__XXX
 SG_ INS_Pos_ECEF_X : 32|32@1- (0.01,0) [-10000000|10000000] "m" Vector__XXX
 SG_ Accuracy_INS_Pos_ECEF_Z : 24|8@1+ (1,0) [0|255] "" Vector__XXX
 SG_ Accuracy_INS_Pos_ECEF_Y : 16|8@1+ (1,0) [0|255] "" Vector__XXX
 SG_ Accuracy_INS_Pos_ECEF_X : 8|8@1+ (1,0) [0|255] "" Vector__XXX
 SG_ Validity_INS_Pos_ECEF_Z : 2|1@1+ (1,0) [0|1] "" Vector__XXX
 SG_ Validity_INS_Pos_ECEF_Y : 1|1@1+ (1,0) [0|1] "" Vector__XXX
 SG_ Validity_INS_Pos_ECEF_X : 0|1@1+ (1,0) [0|1] "" Vector__XXX

BO_ 2304274210 RT_SB_INS_Pos_LLH_2: 8 Vector__XXX
 SG_ INS_Pos_LLH_Altitude : 32|32@1- (0.001,0) [-1000|100000] "m" Vector__XXX
 SG_ INS_Pos_LLH_Longitude : 0|32@1- (1e-07,0) [-180|180] "degrees" Vector__XXX

BO_ 2304273954 RT_SB_INS_Pos_LLH_1: 8 Vector__XXX
 SG_ INS_Pos_LLH_Latitude : 32|32@1- (1e-07,0) [-90|90] "degrees" Vector__XXX
 SG_ Accuracy_INS_Pos_LLH_Altitude : 24|8@1+ (1,0) [0|255] "" Vector__XXX
 SG_ Accuracy_INS_Pos_LLH_Longitude : 16|8@1+ (1,0) [0|255] "" Vector__XXX
 SG_ Accuracy_INS_Pos_LLH_Latitude : 8|8@1+ (1,0) [0|255] "" Vector__XXX
 SG_ Validity_INS_Pos_LLH_Altitude : 2|1@1+ (1,0) [0|1] "" Vector__XXX
 SG_ Validity_INS_Pos_LLH_Longitude : 1|1@1+ (1,0) [0|1] "" Vector__XXX
 SG_ Validity_INS_Pos_LLH_Latitude : 0|1@1+ (1,0) [0|1] "" Vector__XXX

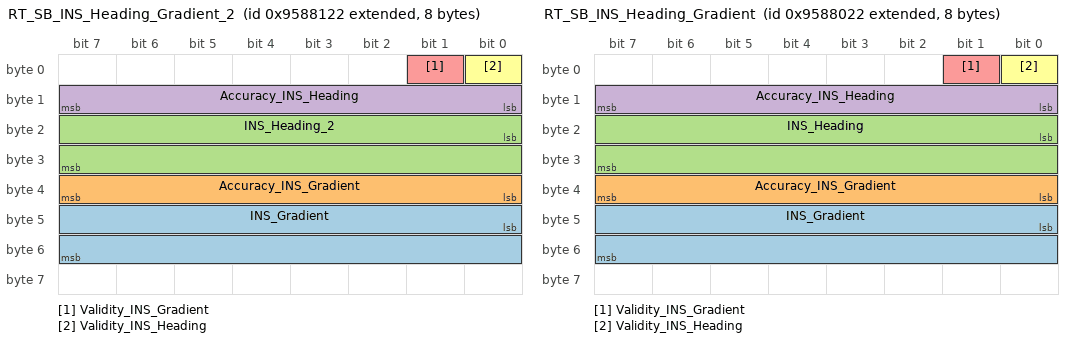
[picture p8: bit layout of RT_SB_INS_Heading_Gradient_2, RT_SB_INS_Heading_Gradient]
BO_ 2304278818 RT_SB_INS_Heading_Gradient_2: 8 Vector__XXX
 SG_ INS_Gradient : 40|16@1- (0.01,0) [-90|90] "degrees" Vector__XXX
 SG_ Accuracy_INS_Gradient : 32|8@1+ (1,0) [0|255] "" Vector__XXX
 SG_ INS_Heading_2 : 16|16@1+ (0.01,0) [0|360] "degrees" Vector__XXX
 SG_ Accuracy_INS_Heading : 8|8@1+ (1,0) [0|255] "" Vector__XXX
 SG_ Validity_INS_Gradient : 1|1@1+ (1,0) [0|1] "" Vector__XXX
 SG_ Validity_INS_Heading : 0|1@1+ (1,0) [0|1] "" Vector__XXX

BO_ 2304278562 RT_SB_INS_Heading_Gradient: 8 Vector__XXX
 SG_ INS_Gradient : 40|16@1- (0.01,0) [-90|90] "degrees" Vector__XXX
 SG_ Accuracy_INS_Gradient : 32|8@1+ (1,0) [0|255] "" Vector__XXX
 SG_ INS_Heading : 16|16@1- (0.01,0) [-180|180] "degrees" Vector__XXX
 SG_ Accuracy_INS_Heading : 8|8@1+ (1,0) [0|255] "" Vector__XXX
 SG_ Validity_INS_Gradient : 1|1@1+ (1,0) [0|1] "" Vector__XXX
 SG_ Validity_INS_Heading : 0|1@1+ (1,0) [0|1] "" Vector__XXX

BO_ 2304273442 RT_SB_INS_Status: 8 Vector__XXX
 SG_ INS_Status : 0|8@1+ (1,0) [0|255] "" Vector__XXX

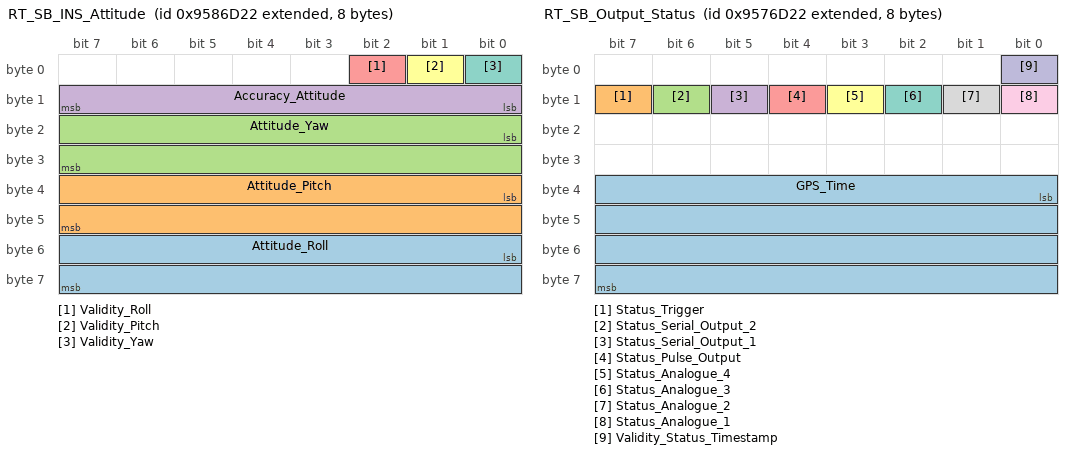
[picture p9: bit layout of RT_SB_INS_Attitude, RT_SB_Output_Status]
BO_ 2304273698 RT_SB_INS_Attitude: 8 Vector__XXX
 SG_ Attitude_Roll : 48|16@1- (0.01,0) [-360|360] "degrees" Vector__XXX
 SG_ Attitude_Pitch : 32|16@1- (0.01,0) [-360|360] "degrees" Vector__XXX
 SG_ Attitude_Yaw : 16|16@1- (0.01,0) [-360|360] "degrees" Vector__XXX
 SG_ Accuracy_Attitude : 8|8@1+ (1,0) [0|255] "" Vector__XXX
 SG_ Validity_Roll : 2|1@1+ (1,0) [0|1] "" Vector__XXX
 SG_ Validity_Pitch : 1|1@1+ (1,0) [0|1] "" Vector__XXX
 SG_ Validity_Yaw : 0|1@1+ (1,0) [0|1] "" Vector__XXX

BO_ 2304208162 RT_SB_Output_Status: 8 Vector__XXX
 SG_ GPS_Time : 32|32@1+ (0.001,0) [0|604800] "s" Vector__XXX
 SG_ Status_Trigger : 15|1@1+ (1,0) [0|1] "" Vector__XXX
 SG_ Status_Serial_Output_2 : 14|1@1+ (1,0) [0|1] "" Vector__XXX
 SG_ Status_Serial_Output_1 : 13|1@1+ (1,0) [0|1] "" Vector__XXX
 SG_ Status_Pulse_Output : 12|1@1+ (1,0) [0|1] "" Vector__XXX
 SG_ Status_Analogue_4 : 11|1@1+ (1,0) [0|1] "" Vector__XXX
 SG_ Status_Analogue_3 : 10|1@1+ (1,0) [0|1] "" Vector__XXX
 SG_ Status_Analogue_2 : 9|1@1+ (1,0) [0|1] "" Vector__XXX
 SG_ Status_Analogue_1 : 8|1@1+ (1,0) [0|1] "" Vector__XXX
 SG_ Validity_Status_Timestamp : 0|1@1+ (1,0) [0|0] "" Vector__XXX

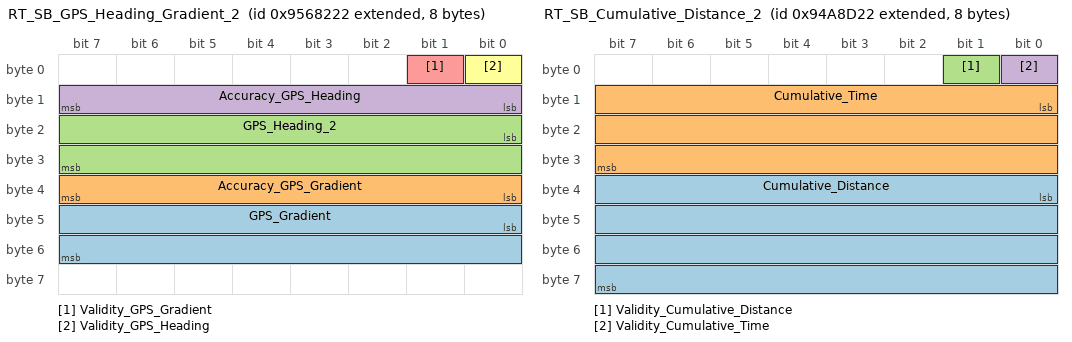
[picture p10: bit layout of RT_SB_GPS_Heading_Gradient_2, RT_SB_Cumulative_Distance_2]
BO_ 2304148002 RT_SB_GPS_Heading_Gradient_2: 8 Vector__XXX
 SG_ GPS_Gradient : 40|16@1- (0.01,0) [-90|90] "degrees" Vector__XXX
 SG_ Accuracy_GPS_Gradient : 32|8@1+ (1,0) [0|255] "" Vector__XXX
 SG_ GPS_Heading_2 : 16|16@1+ (0.01,0) [0|360] "degrees" Vector__XXX
 SG_ Accuracy_GPS_Heading : 8|8@1+ (1,0) [0|255] "" Vector__XXX
 SG_ Validity_GPS_Gradient : 1|1@1+ (1,0) [0|1] "" Vector__XXX
 SG_ Validity_GPS_Heading : 0|1@1+ (1,0) [0|1] "" Vector__XXX

BO_ 2303364386 RT_SB_Cumulative_Distance_2: 8 Vector__XXX
 SG_ Cumulative_Distance : 32|32@1+ (0.001,0) [0|4294967] "m" Vector__XXX
 SG_ Cumulative_Time : 8|24@1+ (0.01,0) [0|167772] "s" Vector__XXX
 SG_ Validity_Cumulative_Distance : 1|1@1+ (1,0) [0|0] "" Vector__XXX
 SG_ Validity_Cumulative_Time : 0|1@1+ (1,0) [0|0] "" Vector__XXX

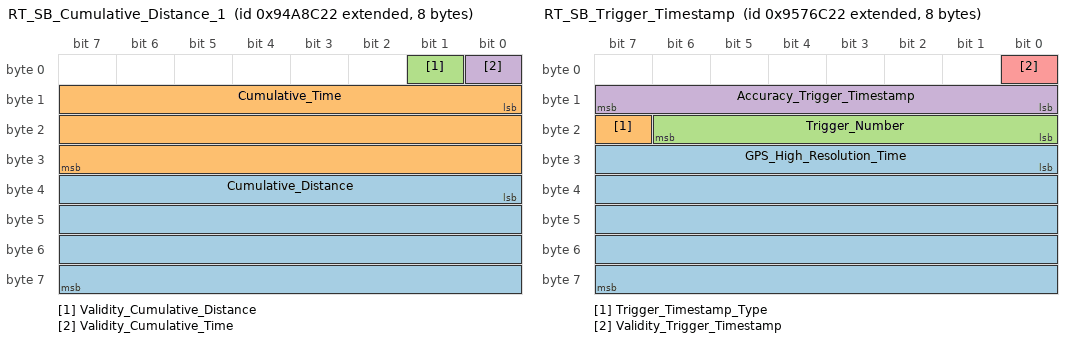
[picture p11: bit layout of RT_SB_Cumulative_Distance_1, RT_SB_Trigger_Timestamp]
BO_ 2303364130 RT_SB_Cumulative_Distance_1: 8 Vector__XXX
 SG_ Cumulative_Distance : 32|32@1+ (0.001,0) [0|4294967] "m" Vector__XXX
 SG_ Cumulative_Time : 8|24@1+ (0.01,0) [0|167772] "s" Vector__XXX
 SG_ Validity_Cumulative_Distance : 1|1@1+ (1,0) [0|0] "" Vector__XXX
 SG_ Validity_Cumulative_Time : 0|1@1+ (1,0) [0|0] "" Vector__XXX

BO_ 2304207906 RT_SB_Trigger_Timestamp: 8 Vector__XXX
 SG_ GPS_High_Resolution_Time : 24|40@1+ (1e-06,0) [0|604800] "s" Vector__XXX
 SG_ Trigger_Timestamp_Type : 23|1@1+ (1,0) [0|1] "" Vector__XXX
 SG_ Trigger_Number : 16|7@1+ (1,1) [0|128] "" Vector__XXX
 SG_ Accuracy_Trigger_Timestamp : 8|8@1+ (1,0) [0|255] "" Vector__XXX
 SG_ Validity_Trigger_Timestamp : 0|1@1+ (1,0) [0|0] "" Vector__XXX

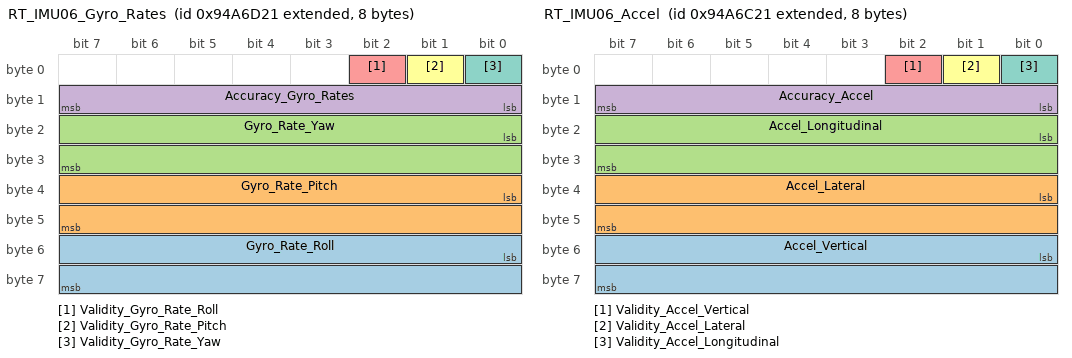
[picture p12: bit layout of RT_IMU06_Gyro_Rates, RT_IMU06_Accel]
BO_ 2303356193 RT_IMU06_Gyro_Rates: 8 Vector__XXX
 SG_ Gyro_Rate_Roll : 48|16@1- (0.01,0) [-327|327] "degrees/s" Vector__XXX
 SG_ Gyro_Rate_Pitch : 32|16@1- (0.01,0) [-327|327] "degrees/s" Vector__XXX
 SG_ Gyro_Rate_Yaw : 16|16@1- (0.01,0) [-327|327] "degrees/s" Vector__XXX
 SG_ Accuracy_Gyro_Rates : 8|8@1+ (1,0) [0|0] "" Vector__XXX
 SG_ Validity_Gyro_Rate_Roll : 2|1@1+ (1,0) [0|1] "" Vector__XXX
 SG_ Validity_Gyro_Rate_Pitch : 1|1@1+ (1,0) [0|1] "" Vector__XXX
 SG_ Validity_Gyro_Rate_Yaw : 0|1@1+ (1,0) [0|1] "" Vector__XXX

BO_ 2303355937 RT_IMU06_Accel: 8 Vector__XXX
 SG_ Accel_Vertical : 48|16@1- (0.001,0) [-65|65] "g" Vector__XXX
 SG_ Accel_Lateral : 32|16@1- (0.001,0) [-65|65] "g" Vector__XXX
 SG_ Accel_Longitudinal : 16|16@1- (0.001,0) [-65|65] "g" Vector__XXX
 SG_ Accuracy_Accel : 8|8@1+ (1,0) [0|255] "" Vector__XXX
 SG_ Validity_Accel_Vertical : 2|1@1+ (1,0) [0|0] "" Vector__XXX
 SG_ Validity_Accel_Lateral : 1|1@1+ (1,0) [0|0] "" Vector__XXX
 SG_ Validity_Accel_Longitudinal : 0|1@1+ (1,0) [0|0] "" Vector__XXX

BO_ 2303360034 RT_SB_Speed: 8 Vector__XXX
 SG_ Speed : 16|32@1- (1e-05,0) [-20000|20000] "m/s" Vector__XXX
 SG_ Accuracy_Speed : 8|8@1+ (1,0) [0|255] "" Vector__XXX
 SG_ Validity_Speed : 0|1@1+ (1,0) [0|0] "" Vector__XXX

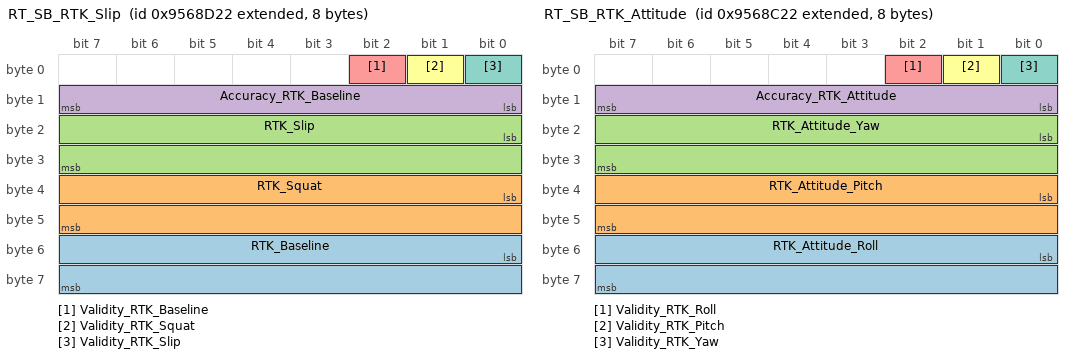
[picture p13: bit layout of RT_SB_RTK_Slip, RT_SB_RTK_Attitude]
BO_ 2304150818 RT_SB_RTK_Slip: 8 Vector__XXX
 SG_ RTK_Baseline : 48|16@1+ (1,0) [0|65535] "mm" Vector__XXX
 SG_ RTK_Squat : 32|16@1- (0.01,0) [-360|360] "degrees" Vector__XXX
 SG_ RTK_Slip : 16|16@1- (0.01,0) [-360|360] "degrees" Vector__XXX
 SG_ Accuracy_RTK_Baseline : 8|8@1+ (1,0) [0|255] "" Vector__XXX
 SG_ Validity_RTK_Baseline : 2|1@1+ (1,0) [0|1] "" Vector__XXX
 SG_ Validity_RTK_Squat : 1|1@1+ (1,0) [0|1] "" Vector__XXX
 SG_ Validity_RTK_Slip : 0|1@1+ (1,0) [0|1] "" Vector__XXX

BO_ 2304150562 RT_SB_RTK_Attitude: 8 Vector__XXX
 SG_ RTK_Attitude_Roll : 48|16@1- (0.01,0) [-90|90] "degrees" Vector__XXX
 SG_ RTK_Attitude_Pitch : 32|16@1- (0.01,0) [-90|90] "degrees" Vector__XXX
 SG_ RTK_Attitude_Yaw : 16|16@1- (0.01,0) [-360|360] "degrees" Vector__XXX
 SG_ Accuracy_RTK_Attitude : 8|8@1+ (1,0) [0|255] "" Vector__XXX
 SG_ Validity_RTK_Roll : 2|1@1+ (1,0) [0|1] "" Vector__XXX
 SG_ Validity_RTK_Pitch : 1|1@1+ (1,0) [0|1] "" Vector__XXX
 SG_ Validity_RTK_Yaw : 0|1@1+ (1,0) [0|1] "" Vector__XXX

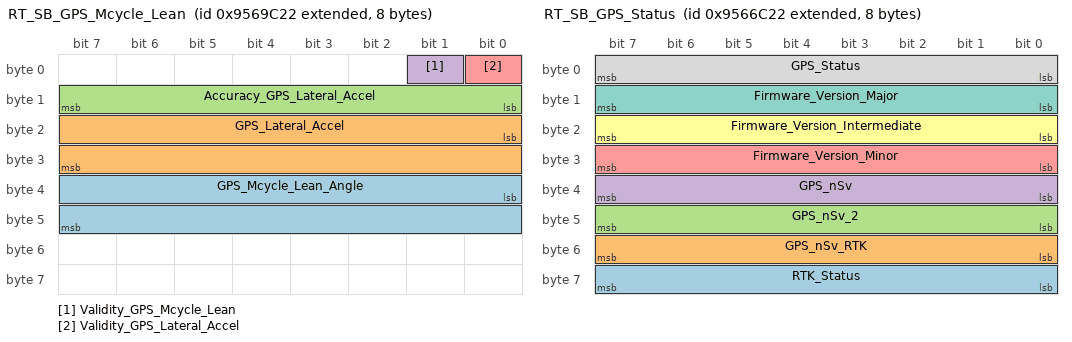
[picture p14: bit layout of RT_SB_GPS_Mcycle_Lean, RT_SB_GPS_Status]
BO_ 2304154658 RT_SB_GPS_Mcycle_Lean: 8 Vector__XXX
 SG_ GPS_Mcycle_Lean_Angle : 32|16@1- (0.01,0) [-90|90] "degrees" Vector__XXX
 SG_ GPS_Lateral_Accel : 16|16@1- (0.001,0) [-65|65] "g" Vector__XXX
 SG_ Accuracy_GPS_Lateral_Accel : 8|8@1+ (1,0) [0|255] "" Vector__XXX
 SG_ Validity_GPS_Mcycle_Lean : 1|1@1+ (1,0) [0|1] "" Vector__XXX
 SG_ Validity_GPS_Lateral_Accel : 0|1@1+ (1,0) [0|1] "" Vector__XXX

BO_ 2304142370 RT_SB_GPS_Status: 8 Vector__XXX
 SG_ RTK_Status : 56|8@1+ (1,0) [0|255] "" Vector__XXX
 SG_ GPS_nSv_RTK : 48|8@1+ (1,0) [0|16] "" Vector__XXX
 SG_ GPS_nSv_2 : 40|8@1+ (1,0) [0|16] "" Vector__XXX
 SG_ GPS_nSv : 32|8@1+ (1,0) [0|16] "" Vector__XXX
 SG_ Firmware_Version_Minor : 24|8@1+ (1,0) [0|255] "" Vector__XXX
 SG_ Firmware_Version_Intermediate : 16|8@1+ (1,0) [0|255] "" Vector__XXX
 SG_ Firmware_Version_Major : 8|8@1+ (1,0) [0|255] "" Vector__XXX
 SG_ GPS_Status : 0|8@1+ (1,0) [0|255] "" Vector__XXX

BO_ 2304143650 RT_SB_GPS_Pos_ECEF_2: 8 Vector__XXX
 SG_ GPS_Pos_ECEF_Z : 32|32@1- (0.01,0) [-10000000|10000000] "m" Vector__XXX
 SG_ GPS_Pos_ECEF_Y : 0|32@1- (0.01,0) [-10000000|10000000] "m" Vector__XXX

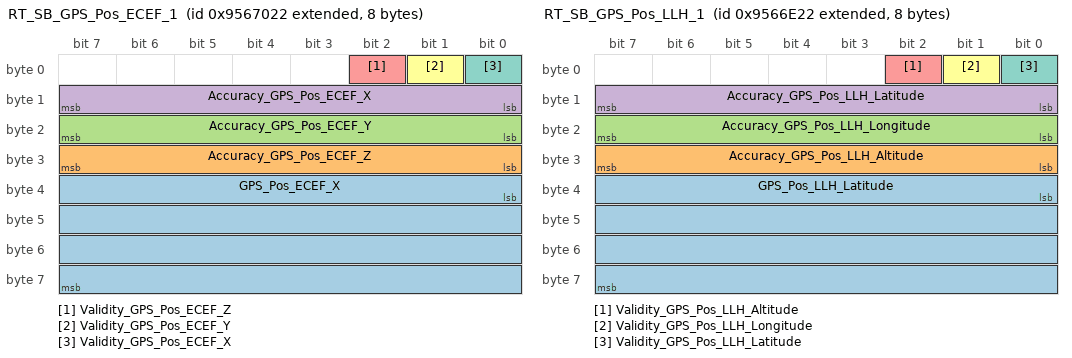
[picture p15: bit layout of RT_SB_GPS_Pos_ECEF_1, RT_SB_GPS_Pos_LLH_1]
BO_ 2304143394 RT_SB_GPS_Pos_ECEF_1: 8 Vector__XXX
 SG_ GPS_Pos_ECEF_X : 32|32@1- (0.01,0) [-10000000|10000000] "m" Vector__XXX
 SG_ Accuracy_GPS_Pos_ECEF_Z : 24|8@1+ (1,0) [0|255] "" Vector__XXX
 SG_ Accuracy_GPS_Pos_ECEF_Y : 16|8@1+ (1,0) [0|255] "" Vector__XXX
 SG_ Accuracy_GPS_Pos_ECEF_X : 8|8@1+ (1,0) [0|255] "" Vector__XXX
 SG_ Validity_GPS_Pos_ECEF_Z : 2|1@1+ (1,0) [0|1] "" Vector__XXX
 SG_ Validity_GPS_Pos_ECEF_Y : 1|1@1+ (1,0) [0|1] "" Vector__XXX
 SG_ Validity_GPS_Pos_ECEF_X : 0|1@1+ (1,0) [0|1] "" Vector__XXX

BO_ 2304143138 RT_SB_GPS_Pos_LLH_2: 8 Vector__XXX
 SG_ GPS_Pos_LLH_Altitude : 32|32@1- (0.001,0) [-1000|100000] "m" Vector__XXX
 SG_ GPS_Pos_LLH_Longitude : 0|32@1- (1e-07,0) [-180|180] "degrees" Vector__XXX

BO_ 2304142882 RT_SB_GPS_Pos_LLH_1: 8 Vector__XXX
 SG_ GPS_Pos_LLH_Latitude : 32|32@1- (1e-07,0) [-90|90] "degrees" Vector__XXX
 SG_ Accuracy_GPS_Pos_LLH_Altitude : 24|8@1+ (1,0) [0|255] "" Vector__XXX
 SG_ Accuracy_GPS_Pos_LLH_Longitude : 16|8@1+ (1,0) [0|255] "" Vector__XXX
 SG_ Accuracy_GPS_Pos_LLH_Latitude : 8|8@1+ (1,0) [0|255] "" Vector__XXX
 SG_ Validity_GPS_Pos_LLH_Altitude : 2|1@1+ (1,0) [0|1] "" Vector__XXX
 SG_ Validity_GPS_Pos_LLH_Longitude : 1|1@1+ (1,0) [0|1] "" Vector__XXX
 SG_ Validity_GPS_Pos_LLH_Latitude : 0|1@1+ (1,0) [0|1] "" Vector__XXX

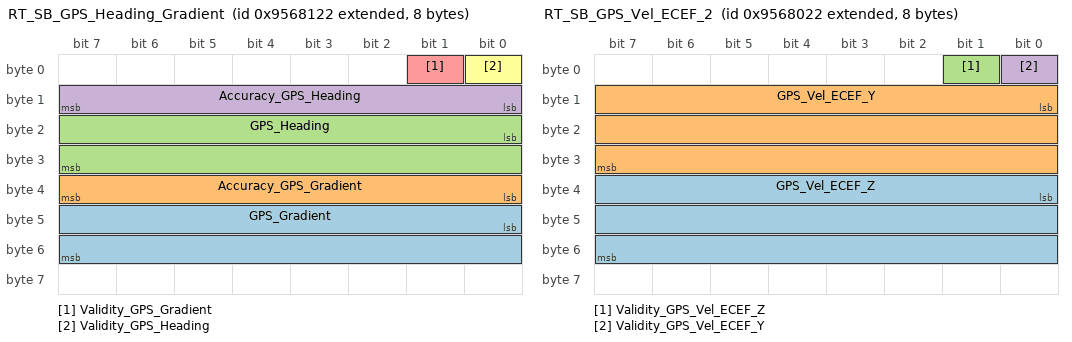
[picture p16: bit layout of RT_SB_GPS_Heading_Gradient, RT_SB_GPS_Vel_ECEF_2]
BO_ 2304147746 RT_SB_GPS_Heading_Gradient: 8 Vector__XXX
 SG_ GPS_Gradient : 40|16@1- (0.01,0) [-90|90] "degrees" Vector__XXX
 SG_ Accuracy_GPS_Gradient : 32|8@1+ (1,0) [0|255] "" Vector__XXX
 SG_ GPS_Heading : 16|16@1- (0.01,0) [-180|180] "degrees" Vector__XXX
 SG_ Accuracy_GPS_Heading : 8|8@1+ (1,0) [0|255] "" Vector__XXX
 SG_ Validity_GPS_Gradient : 1|1@1+ (1,0) [0|1] "" Vector__XXX
 SG_ Validity_GPS_Heading : 0|1@1+ (1,0) [0|1] "" Vector__XXX

BO_ 2304147490 RT_SB_GPS_Vel_ECEF_2: 8 Vector__XXX
 SG_ GPS_Vel_ECEF_Z : 32|24@1- (0.0001,0) [-838|838] "m/s" Vector__XXX
 SG_ GPS_Vel_ECEF_Y : 8|24@1- (0.0001,0) [-838|838] "m/s" Vector__XXX
 SG_ Validity_GPS_Vel_ECEF_Z : 1|1@1+ (1,0) [0|1] "" Vector__XXX
 SG_ Validity_GPS_Vel_ECEF_Y : 0|1@1+ (1,0) [0|1] "" Vector__XXX

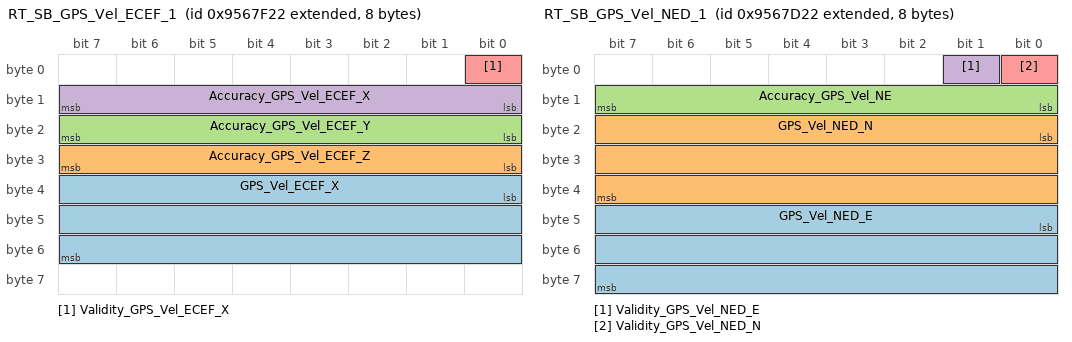
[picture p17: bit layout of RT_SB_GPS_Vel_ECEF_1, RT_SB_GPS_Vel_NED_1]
BO_ 2304147234 RT_SB_GPS_Vel_ECEF_1: 8 Vector__XXX
 SG_ GPS_Vel_ECEF_X : 32|24@1- (0.0001,0) [-838|838] "m/s" Vector__XXX
 SG_ Accuracy_GPS_Vel_ECEF_Z : 24|8@1+ (1,0) [0|255] "" Vector__XXX
 SG_ Accuracy_GPS_Vel_ECEF_Y : 16|8@1+ (1,0) [0|255] "" Vector__XXX
 SG_ Accuracy_GPS_Vel_ECEF_X : 8|8@1+ (1,0) [0|255] "" Vector__XXX
 SG_ Validity_GPS_Vel_ECEF_X : 0|1@1+ (1,0) [0|1] "" Vector__XXX

BO_ 2304146978 RT_SB_GPS_Vel_NED_2: 8 Vector__XXX
 SG_ GPS_Vel_NED_D : 16|24@1- (0.0001,0) [-838|838] "m/s" Vector__XXX
 SG_ Accuracy_GPS_Vel_D : 8|8@1+ (1,0) [0|255] "" Vector__XXX
 SG_ Validity_GPS_Vel_NED_D : 0|1@1+ (1,0) [0|1] "" Vector__XXX

BO_ 2304146722 RT_SB_GPS_Vel_NED_1: 8 Vector__XXX
 SG_ GPS_Vel_NED_E : 40|24@1- (0.0001,0) [-838|838] "m/s" Vector__XXX
 SG_ GPS_Vel_NED_N : 16|24@1- (0.0001,0) [-838|838] "m/s" Vector__XXX
 SG_ Accuracy_GPS_Vel_NE : 8|8@1+ (1,0) [0|255] "" Vector__XXX
 SG_ Validity_GPS_Vel_NED_E : 1|1@1+ (1,0) [0|1] "" Vector__XXX
 SG_ Validity_GPS_Vel_NED_N : 0|1@1+ (1,0) [0|1] "" Vector__XXX

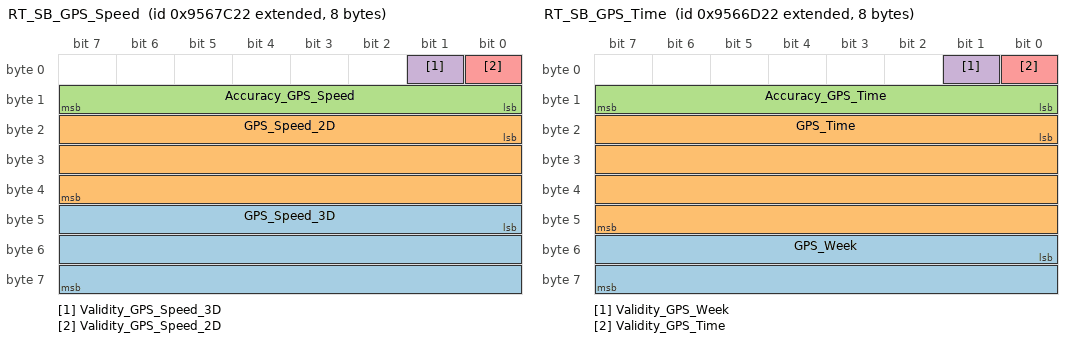
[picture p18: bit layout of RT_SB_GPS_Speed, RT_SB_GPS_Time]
BO_ 2304146466 RT_SB_GPS_Speed: 8 Vector__XXX
 SG_ GPS_Speed_3D : 40|24@1+ (0.0001,0) [0|1675] "m/s" Vector__XXX
 SG_ GPS_Speed_2D : 16|24@1+ (0.0001,0) [0|1675] "m/s" Vector__XXX
 SG_ Accuracy_GPS_Speed : 8|8@1+ (1,0) [0|255] "" Vector__XXX
 SG_ Validity_GPS_Speed_3D : 1|1@1+ (1,0) [0|1] "" Vector__XXX
 SG_ Validity_GPS_Speed_2D : 0|1@1+ (1,0) [0|1] "" Vector__XXX

BO_ 2304142626 RT_SB_GPS_Time: 8 Vector__XXX
 SG_ GPS_Week : 48|16@1+ (1,0) [0|65535] "" Vector__XXX
 SG_ GPS_Time : 16|32@1+ (0.001,0) [0|604800] "s" Vector__XXX
 SG_ Accuracy_GPS_Time : 8|8@1+ (1,0) [0|255] "" Vector__XXX
 SG_ Validity_GPS_Week : 1|1@1+ (1,0) [0|1] "" Vector__XXX
 SG_ Validity_GPS_Time : 0|1@1+ (1,0) [0|1] "" Vector__XXX

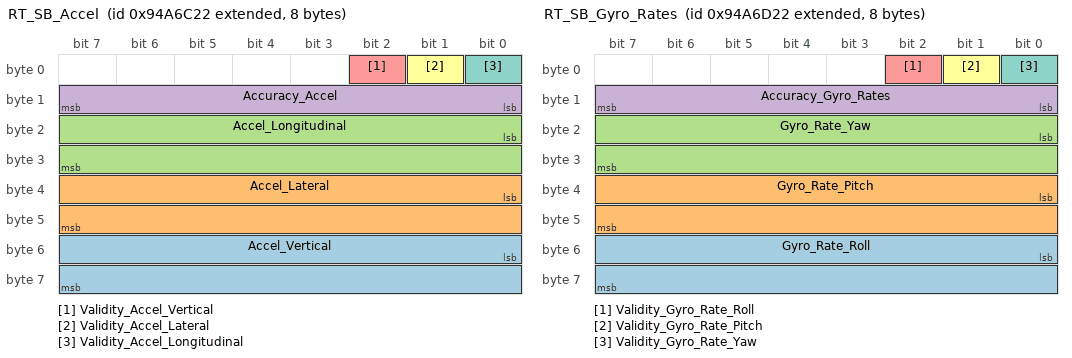
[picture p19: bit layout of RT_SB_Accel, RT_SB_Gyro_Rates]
BO_ 2303355938 RT_SB_Accel: 8 Vector__XXX
 SG_ Accel_Vertical : 48|16@1- (0.001,0) [-65|65] "g" Vector__XXX
 SG_ Accel_Lateral : 32|16@1- (0.001,0) [-65|65] "g" Vector__XXX
 SG_ Accel_Longitudinal : 16|16@1- (0.001,0) [-65|65] "g" Vector__XXX
 SG_ Accuracy_Accel : 8|8@1+ (1,0) [0|255] "" Vector__XXX
 SG_ Validity_Accel_Vertical : 2|1@1+ (1,0) [0|0] "" Vector__XXX
 SG_ Validity_Accel_Lateral : 1|1@1+ (1,0) [0|0] "" Vector__XXX
 SG_ Validity_Accel_Longitudinal : 0|1@1+ (1,0) [0|0] "" Vector__XXX

BO_ 2303356194 RT_SB_Gyro_Rates: 8 Vector__XXX
 SG_ Gyro_Rate_Roll : 48|16@1- (0.01,0) [-327|327] "degrees/s" Vector__XXX
 SG_ Gyro_Rate_Pitch : 32|16@1- (0.01,0) [-327|327] "degrees/s" Vector__XXX
 SG_ Gyro_Rate_Yaw : 16|16@1- (0.01,0) [-327|327] "degrees/s" Vector__XXX
 SG_ Accuracy_Gyro_Rates : 8|8@1+ (1,0) [0|0] "" Vector__XXX
 SG_ Validity_Gyro_Rate_Roll : 2|1@1+ (1,0) [0|1] "" Vector__XXX
 SG_ Validity_Gyro_Rate_Pitch : 1|1@1+ (1,0) [0|1] "" Vector__XXX
 SG_ Validity_Gyro_Rate_Yaw : 0|1@1+ (1,0) [0|1] "" Vector__XXX

CM_ SG_ 2304279330 INS_Vel_Sideways_2D "Sideways Velocity in the vehicle body axes, 2D (no vertical component) .  +ve for motion to the vehicle RHS.";
CM_ SG_ 2304279330 INS_Vel_Forwards_2D "Forwards Velocity in the vehicle body axes, 2D (no vertical component) .";
CM_ SG_ 2304279330 Accuracy_INS_Vel_Body "Accuracy of INS body axis velocities (forward velocity and sideways velocity)";
CM_ SG_ 2304279330 Validity_INS_Vel_Sideways "Valid when bit is set, invalid when bit is clear.";
CM_ SG_ 2304279330 Validity_INS_Vel_Forwards "Valid when bit is set, invalid when bit is clear.";
CM_ SG_ 2303360036 Accuracy_Speed "Dimensionless.  Lower values imply but do not guarantee better accuracy than higher values.";
CM_ SG_ 2303360036 Validity_Speed "Valid when bit is set, invalid when bit is clear.";
CM_ SG_ 2304142628 GPS_Time "GPS time is the time in seconds since midnight GMT on Saturday night.";
CM_ SG_ 2304142628 Validity_GPS_Week "Valid when bit is set, invalid when bit is clear.";
CM_ SG_ 2304142628 Validity_GPS_Time "Valid when bit is set, invalid when bit is clear.";
CM_ SG_ 2304142884 Accuracy_GPS_Pos_LLH_Altitude "This accuracy value applies to both 2D and 3D GPS speed.";
CM_ SG_ 2304142884 Accuracy_GPS_Pos_LLH_Longitude "This accuracy value applies to both 2D and 3D GPS speed.";
CM_ SG_ 2304142884 Accuracy_GPS_Pos_LLH_Latitude "This accuracy value applies to both 2D and 3D GPS speed.";
CM_ SG_ 2304142884 Validity_GPS_Pos_LLH_Altitude "Valid when bit is set, invalid when bit is clear.";
CM_ SG_ 2304142884 Validity_GPS_Pos_LLH_Longitude "Valid when bit is set, invalid when bit is clear.";
CM_ SG_ 2304142884 Validity_GPS_Pos_LLH_Latitude "Valid when bit is set, invalid when bit is clear.";
CM_ SG_ 2304146468 GPS_Speed_3D "This is GPS scalar 3D speed - scalar speed with the local Z axis component included.";
CM_ SG_ 2304146468 GPS_Speed_2D "This is GPS scalar 2D speed - scalar speed with no local Z axis component included.";
CM_ SG_ 2304146468 Accuracy_GPS_Speed "This accuracy value applies to both 2D and 3D GPS speed.";
CM_ SG_ 2304146468 Validity_GPS_Speed_3D "Valid when bit is set, invalid when bit is clear.";
CM_ SG_ 2304146468 Validity_GPS_Speed_2D "Valid when bit is set, invalid when bit is clear.";
CM_ SG_ 2304209698 Final_Speed "Speed at end of triggered test";
CM_ SG_ 2304209698 Validity_Final_Speed "Valid when bit is set, invalid when bit is clear.";
CM_ SG_ 2304209442 Initial_Heading "Heading (track) at start of triggered test";
CM_ SG_ 2304209442 Initial_Speed "Speed at start of triggered test";
CM_ SG_ 2304209442 Validity_Initial_Heading "Valid when bit is set, invalid when bit is clear.";
CM_ SG_ 2304209442 Validity_Initial_Speed "Valid when bit is set, invalid when bit is clear.";
CM_ SG_ 2304209186 Path_Distance_2D "2D path distance (horizontal components only)";
CM_ SG_ 2304209186 Direct_Distance "Direct distance from start of test to current position";
CM_ SG_ 2304208930 Deviation_Distance "Current deviation distance from a line projected along the initial heading at start of test, +ve for deviation to the right.";
CM_ SG_ 2304208930 Forward_Distance "Current forward distance from start of test in direction of initial heading at start of test";
CM_ SG_ 2304208674 Path_Distance_3D "3D path distance";
CM_ SG_ 2304208418 Triggered_Time "Cumulative time from start of triggered test to current time.";
CM_ SG_ 2304208418 Average_Accel "Average acceleration from start of triggered test to current time.";
CM_ SG_ 2304208418 MFDD "Mean fully-developed decelleration of triggered test.  Thresholds used are as set in the logger configuration.";
CM_ SG_ 2304208418 Validity_Triggered_Time "Valid when bit is set, invalid when bit is clear.";
CM_ SG_ 2304208418 Validity_Average_Accel "Valid when bit is set, invalid when bit is clear.";
CM_ SG_ 2304208418 Validity_MFDD "Valid when bit is set, invalid when bit is clear.";
CM_ SG_ 2303355940 Accel_Vertical "Vertical acceleration.  This is positive when the vehicle accelerates in an upwards direction, e.g. when travelling through a dip.";
CM_ SG_ 2303355940 Accel_Lateral "Lateral acceleration.  This is positive when the vehicle accelerates towards the right, e.g. when cornering around a right-hand bend.";
CM_ SG_ 2303355940 Accel_Longitudinal "Longitudinal acceleration.  This is positive when the vehicle accelerates in a forwards direction.";
CM_ SG_ 2303355940 Accuracy_Accel "Dimensionless.  Lower values imply but do not guarantee better accuracy than higher values.";
CM_ SG_ 2303355940 Validity_Accel_Vertical "Valid when bit is set, invalid when bit is clear.";
CM_ SG_ 2303355940 Validity_Accel_Lateral "Valid when bit is set, invalid when bit is clear.";
CM_ SG_ 2303355940 Validity_Accel_Longitudinal "Valid when bit is set, invalid when bit is clear.";
CM_ SG_ 2304351778 Virtual_4_Slip "Slip is defined as the difference between yaw and heading.";
CM_ SG_ 2304351778 Virtual_4_Heading "This is GPS heading, the direction that the vehicle is travelling in the local horizontal plane.";
CM_ SG_ 2304351778 Virtual_4_Vel_NED_D "VELNED D velocity.  This is the velocity vector directly downwards towards the Earth centre at the current local Earth surface position.";
CM_ SG_ 2304351522 Virtual_4_Vel_NED_E "VELNED E velocity.  This is the velocity vector directly East at the current local Earth surface position.";
CM_ SG_ 2304351522 Virtual_4_Vel_NED_N "VELNED N velocity.  This is the velocity vector directly North at the current local Earth surface position.";
CM_ SG_ 2304351266 Virtual_4_Offset_Z "Z offset (+ve downwards) of the virtual point in the vehicle body frame.";
CM_ SG_ 2304351266 Virtual_4_Offset_Y "Y offset of the virtual point in the vehicle body frame.";
CM_ SG_ 2304351266 Virtual_4_Offset_X "X offset of the virtual point in the vehicle body frame.";
CM_ SG_ 2304347682 Virtual_3_Slip "Slip is defined as the difference between yaw and heading.";
CM_ SG_ 2304347682 Virtual_3_Heading "This is GPS heading, the direction that the vehicle is travelling in the local horizontal plane.";
CM_ SG_ 2304347682 Virtual_3_Vel_NED_D "VELNED D velocity.  This is the velocity vector directly downwards towards the Earth centre at the current local Earth surface position.";
CM_ SG_ 2304347426 Virtual_3_Vel_NED_E "VELNED E velocity.  This is the velocity vector directly East at the current local Earth surface position.";
CM_ SG_ 2304347426 Virtual_3_Vel_NED_N "VELNED N velocity.  This is the velocity vector directly North at the current local Earth surface position.";
CM_ SG_ 2304347170 Virtual_3_Offset_Z "Z offset (+ve downwards) of the virtual point in the vehicle body frame.";
CM_ SG_ 2304347170 Virtual_3_Offset_Y "Y offset of the virtual point in the vehicle body frame.";
CM_ SG_ 2304347170 Virtual_3_Offset_X "X offset of the virtual point in the vehicle body frame.";
CM_ SG_ 2304343586 Virtual_2_Slip "Slip is defined as the difference between yaw and heading.";
CM_ SG_ 2304343586 Virtual_2_Heading "This is GPS heading, the direction that the vehicle is travelling in the local horizontal plane.";
CM_ SG_ 2304343586 Virtual_2_Vel_NED_D "VELNED D velocity.  This is the velocity vector directly downwards towards the Earth centre at the current local Earth surface position.";
CM_ SG_ 2304343330 Virtual_2_Vel_NED_E "VELNED E velocity.  This is the velocity vector directly East at the current local Earth surface position.";
CM_ SG_ 2304343330 Virtual_2_Vel_NED_N "VELNED N velocity.  This is the velocity vector directly North at the current local Earth surface position.";
CM_ SG_ 2304343074 Virtual_2_Offset_Z "Z offset (+ve downwards) of the virtual point in the vehicle body frame.";
CM_ SG_ 2304343074 Virtual_2_Offset_Y "Y offset of the virtual point in the vehicle body frame.";
CM_ SG_ 2304343074 Virtual_2_Offset_X "X offset of the virtual point in the vehicle body frame.";
CM_ SG_ 2304339490 Virtual_1_Slip "Slip is defined as the difference between yaw and heading.";
CM_ SG_ 2304339490 Virtual_1_Heading "This is GPS heading, the direction that the vehicle is travelling in the local horizontal plane.";
CM_ SG_ 2304339490 Virtual_1_Vel_NED_D "VELNED D velocity.  This is the velocity vector directly downwards towards the Earth centre at the current local Earth surface position.";
CM_ SG_ 2304339234 Virtual_1_Vel_NED_E "VELNED E velocity.  This is the velocity vector directly East at the current local Earth surface position.";
CM_ SG_ 2304339234 Virtual_1_Vel_NED_N "VELNED N velocity.  This is the velocity vector directly North at the current local Earth surface position.";
CM_ SG_ 2304338978 Virtual_1_Offset_Z "Z offset (+ve downwards) of the virtual point in the vehicle body frame.";
CM_ SG_ 2304338978 Virtual_1_Offset_Y "Y offset of the virtual point in the vehicle body frame.";
CM_ SG_ 2304338978 Virtual_1_Offset_X "X offset of the virtual point in the vehicle body frame.";
CM_ SG_ 2304279074 INS_Squat "Squat is defined as the difference between pitch and gradient";
CM_ SG_ 2304279074 Accuracy_INS_Squat "Dimensionless.  Lower values imply but do not guarantee better accuracy than higher values.";
CM_ SG_ 2304279074 INS_Slip "Slip is defined as the difference between yaw and heading";
CM_ SG_ 2304279074 Accuracy_INS_Slip "Dimensionless.  Lower values imply but do not guarantee better accuracy than higher values.";
CM_ SG_ 2304278306 INS_Vel_ECEF_Z "ECEF Z velocity.  The ECEF Z axis originates from the Earth centre, and the positive Z axis intersects the Earth surface at the North Pole.";
CM_ SG_ 2304278306 INS_Vel_ECEF_Y "ECEF Y velocity.  The ECEF Y axis originates from the Earth centre, and the positive Y axis intersects the Earth surface at zero degrees latittude and 90 degrees longitude.";
CM_ SG_ 2304278306 Validity_INS_Vel_ECEF_Z "Valid when bit is set, invalid when bit is clear.";
CM_ SG_ 2304278306 Validity_INS_Vel_ECEF_Y "Valid when bit is set, invalid when bit is clear.";
CM_ SG_ 2304278050 INS_Vel_ECEF_X "ECEF X velocity.  The ECEF X axis originates from the Earth centre, and the positive X axis intersects the Earth surface at zero degrees latittude and zero degrees longitude (the intersection of the equator and the prime meridian).";
CM_ SG_ 2304278050 Validity_INS_Vel_ECEF_X "Valid when bit is set, invalid when bit is clear.";
CM_ SG_ 2304277794 INS_Vel_NED_D "VELNED D velocity.  This is the velocity vector directly downwards towards the Earth centre at the current local Earth surface position.";
CM_ SG_ 2304277794 Validity_INS_Vel_NED_D "Valid when bit is set, invalid when bit is clear.";
CM_ SG_ 2304277538 INS_Vel_NED_E "VELNED E velocity.  This is the velocity vector directly East at the current local Earth surface position.";
CM_ SG_ 2304277538 INS_Vel_NED_N "VELNED N velocity.  This is the velocity vector directly North at the current local Earth surface position.";
CM_ SG_ 2304277538 Validity_INS_Vel_NED_E "Valid when bit is set, invalid when bit is clear.";
CM_ SG_ 2304277538 Validity_INS_Vel_NED_N "Valid when bit is set, invalid when bit is clear.";
CM_ SG_ 2304274722 INS_Pos_ECEF_Z "ECEF Z position.  The ECEF Z axis originates from the Earth centre, and the positive Z axis intersects the Earth surface at the North Pole.";
CM_ SG_ 2304274722 INS_Pos_ECEF_Y "ECEF Y position.  The ECEF Y axis originates from the Earth centre, and the positive Y axis intersects the Earth surface at zero degrees latittude and 90 degrees longitude.";
CM_ SG_ 2304274466 INS_Pos_ECEF_X "ECEF X position.  The ECEF X axis originates from the Earth centre, and the positive X axis intersects the Earth surface at zero degrees latittude and zero degrees longitude (the intersection of the equator and the prime meridian).";
CM_ SG_ 2304274466 Accuracy_INS_Pos_ECEF_Z "Dimensionless.  Lower values imply but do not guarantee better accuracy than higher values.";
CM_ SG_ 2304274466 Accuracy_INS_Pos_ECEF_Y "Dimensionless.  Lower values imply but do not guarantee better accuracy than higher values.";
CM_ SG_ 2304274466 Accuracy_INS_Pos_ECEF_X "Dimensionless.  Lower values imply but do not guarantee better accuracy than higher values.";
CM_ SG_ 2304274466 Validity_INS_Pos_ECEF_Z "Valid when bit is set, invalid when bit is clear.";
CM_ SG_ 2304274466 Validity_INS_Pos_ECEF_Y "Valid when bit is set, invalid when bit is clear.";
CM_ SG_ 2304274466 Validity_INS_Pos_ECEF_X "Valid when bit is set, invalid when bit is clear.";
CM_ SG_ 2304273954 Accuracy_INS_Pos_LLH_Altitude "This accuracy value applies to both 2D and 3D GPS speed.";
CM_ SG_ 2304273954 Accuracy_INS_Pos_LLH_Longitude "This accuracy value applies to both 2D and 3D GPS speed.";
CM_ SG_ 2304273954 Accuracy_INS_Pos_LLH_Latitude "This accuracy value applies to both 2D and 3D GPS speed.";
CM_ SG_ 2304273954 Validity_INS_Pos_LLH_Altitude "Valid when bit is set, invalid when bit is clear.";
CM_ SG_ 2304273954 Validity_INS_Pos_LLH_Longitude "Valid when bit is set, invalid when bit is clear.";
CM_ SG_ 2304273954 Validity_INS_Pos_LLH_Latitude "Valid when bit is set, invalid when bit is clear.";
CM_ SG_ 2304278818 INS_Gradient "This is GPS gradient, i.e. the vertical direction that the vehicle is travelling, NOT pointing (pitch).";
CM_ SG_ 2304278818 Accuracy_INS_Gradient "Dimensionless.  Lower values imply but do not guarantee better accuracy than higher values.";
CM_ SG_ 2304278818 INS_Heading_2 "This is GPS heading in the range 0 - 360°, the direction that the vehicle is travelling in the local horizontal plane.";
CM_ SG_ 2304278818 Accuracy_INS_Heading "Dimensionless.  Lower values imply but do not guarantee better accuracy than higher values.";
CM_ SG_ 2304278818 Validity_INS_Gradient "Valid when bit is set, invalid when bit is clear.";
CM_ SG_ 2304278818 Validity_INS_Heading "Valid when bit is set, invalid when bit is clear.";
CM_ SG_ 2304278562 INS_Gradient "This is GPS gradient, i.e. the vertical direction that the vehicle is travelling, NOT pointing (pitch).";
CM_ SG_ 2304278562 Accuracy_INS_Gradient "Dimensionless.  Lower values imply but do not guarantee better accuracy than higher values.";
CM_ SG_ 2304278562 INS_Heading "This is GPS heading, the direction that the vehicle is travelling in the local horizontal plane.";
CM_ SG_ 2304278562 Accuracy_INS_Heading "Dimensionless.  Lower values imply but do not guarantee better accuracy than higher values.";
CM_ SG_ 2304278562 Validity_INS_Gradient "Valid when bit is set, invalid when bit is clear.";
CM_ SG_ 2304278562 Validity_INS_Heading "Valid when bit is set, invalid when bit is clear.";
CM_ SG_ 2304208162 GPS_Time "GPS time is the time in seconds since midnight GMT on Saturday night.";
CM_ SG_ 2304208162 Status_Trigger "Status of the trigger input";
CM_ SG_ 2304208162 Status_Serial_Output_2 "Status output of serial port 1";
CM_ SG_ 2304208162 Status_Serial_Output_1 "Status output of serial port 1";
CM_ SG_ 2304208162 Status_Pulse_Output "Pulse output activity status";
CM_ SG_ 2304208162 Status_Analogue_4 "Analogue output status for channel 4.";
CM_ SG_ 2304208162 Status_Analogue_3 "Analogue output status for channel 3.";
CM_ SG_ 2304208162 Status_Analogue_2 "Analogue output status for channel 1.  ";
CM_ SG_ 2304208162 Status_Analogue_1 "Analogue output status for channel 1.  ";
CM_ SG_ 2304208162 Validity_Status_Timestamp "Valid when bit is set, invalid when bit is clear.";
CM_ SG_ 2304148002 GPS_Gradient "This is GPS gradient, i.e. the vertical direction that the vehicle is travelling, NOT pointing (pitch).";
CM_ SG_ 2304148002 Accuracy_GPS_Gradient "Dimensionless.  Lower values imply but do not guarantee better accuracy than higher values.";
CM_ SG_ 2304148002 GPS_Heading_2 "This is GPS heading in the range 0 - 360°, the direction that the vehicle is travelling in the local horizontal plane.";
CM_ SG_ 2304148002 Accuracy_GPS_Heading "Dimensionless.  Lower values imply but do not guarantee better accuracy than higher values.";
CM_ SG_ 2304148002 Validity_GPS_Gradient "Valid when bit is set, invalid when bit is clear.";
CM_ SG_ 2304148002 Validity_GPS_Heading "Valid when bit is set, invalid when bit is clear.";
CM_ BO_ 2303364386 "This cumulative distance calculation is updated when the trigger is active.";
CM_ SG_ 2303364386 Validity_Cumulative_Distance "Valid when bit is set, invalid when bit is clear.";
CM_ SG_ 2303364386 Validity_Cumulative_Time "Valid when bit is set, invalid when bit is clear.";
CM_ BO_ 2303364130 "This cumulative distance calculation is updated continuously once the first good GPS lock is obtained.";
CM_ SG_ 2303364130 Validity_Cumulative_Distance "Valid when bit is set, invalid when bit is clear.";
CM_ SG_ 2303364130 Validity_Cumulative_Time "Valid when bit is set, invalid when bit is clear.";
CM_ SG_ 2304207906 GPS_High_Resolution_Time "GPS time of week to micro-second resolution.";
CM_ SG_ 2304207906 Trigger_Number "This is the ID of the trigger that generated the event, as marked on the case of the logger";
CM_ SG_ 2304207906 Accuracy_Trigger_Timestamp "Dimensionless.  Lower values imply but do not guarantee better accuracy than higher values.";
CM_ SG_ 2304207906 Validity_Trigger_Timestamp "Valid when bit is set, invalid when bit is clear.";
CM_ SG_ 2303356193 Gyro_Rate_Roll "Roll rate is positive for clockwise rotation when looking at the rear of the vehicle from behind the vehicle.";
CM_ SG_ 2303356193 Gyro_Rate_Pitch "Pitch rate is positive for clockwise rotation when looking at the left hand side of the vehicle from the left of the vehicle.";
CM_ SG_ 2303356193 Gyro_Rate_Yaw "Yaw rate is positive for clockwise rotation when looking down on the vehicle from above.";
CM_ SG_ 2303356193 Accuracy_Gyro_Rates "Dimensionless.  Lower values imply but do not guarantee better accuracy than higher values.";
CM_ SG_ 2303356193 Validity_Gyro_Rate_Roll "Valid when bit is set, invalid when bit is clear.";
CM_ SG_ 2303356193 Validity_Gyro_Rate_Pitch "Valid when bit is set, invalid when bit is clear.";
CM_ SG_ 2303356193 Validity_Gyro_Rate_Yaw "Valid when bit is set, invalid when bit is clear.";
CM_ SG_ 2303355937 Accel_Vertical "Vertical acceleration.  This is positive when the vehicle accelerates in an upwards direction, e.g. when travelling through a dip.";
CM_ SG_ 2303355937 Accel_Lateral "Lateral acceleration.  This is positive when the vehicle accelerates towards the right, e.g. when cornering around a right-hand bend.";
CM_ SG_ 2303355937 Accel_Longitudinal "Longitudinal acceleration.  This is positive when the vehicle accelerates in a forwards direction.";
CM_ SG_ 2303355937 Accuracy_Accel "Dimensionless.  Lower values imply but do not guarantee better accuracy than higher values.";
CM_ SG_ 2303355937 Validity_Accel_Vertical "Valid when bit is set, invalid when bit is clear.";
CM_ SG_ 2303355937 Validity_Accel_Lateral "Valid when bit is set, invalid when bit is clear.";
CM_ SG_ 2303355937 Validity_Accel_Longitudinal "Valid when bit is set, invalid when bit is clear.";
CM_ SG_ 2303360034 Accuracy_Speed "Dimensionless.  Lower values imply but do not guarantee better accuracy than higher values.";
CM_ SG_ 2303360034 Validity_Speed "Valid when bit is set, invalid when bit is clear.";
CM_ SG_ 2304150818 RTK_Baseline "This is the estimated baseline length calculated by the RTK solution.";
CM_ SG_ 2304150818 RTK_Squat "Squat is defined as the difference between pitch and gradient.";
CM_ SG_ 2304150818 RTK_Slip "Slip is defined as the difference between yaw and heading.";
CM_ SG_ 2304150818 Validity_RTK_Baseline "Valid when bit is set, invalid when bit is clear.";
CM_ SG_ 2304150818 Validity_RTK_Squat "Valid when bit is set, invalid when bit is clear.";
CM_ SG_ 2304150818 Validity_RTK_Slip "Valid when bit is set, invalid when bit is clear.";
CM_ SG_ 2304150562 RTK_Attitude_Roll "RTK attitude is determined from the MB-RTK solution only.  Roll is positive for a clockwise rotational displacement relative to the local horizontal plane when looking at the vehicle from the rear of it.";
CM_ SG_ 2304150562 RTK_Attitude_Pitch "RTK attitude is determined from the MB-RTK solution only.  Pitch is positive for a clockwise rotational displacement from the local horizontal plane when looking at the vehicle from the left hand side of it.";
CM_ SG_ 2304150562 RTK_Attitude_Yaw "RTK attitude is determined from the MB-RTK solution only.  Yaw is positive for a clockwise rotational displacement from due North, looking down on the vehicle from above.";
CM_ SG_ 2304150562 Accuracy_RTK_Attitude "Note that RTK yaw is typically up to about 4 times more accurate than RTK pitch or roll.";
CM_ SG_ 2304150562 Validity_RTK_Roll "Valid when bit is set, invalid when bit is clear.";
CM_ SG_ 2304150562 Validity_RTK_Pitch "Valid when bit is set, invalid when bit is clear.";
CM_ SG_ 2304150562 Validity_RTK_Yaw "Valid when bit is set, invalid when bit is clear.";
CM_ SG_ 2304154658 GPS_Mcycle_Lean_Angle "Motorcycle lean angle, derived from rate of change of heading from GPS.  This is the lean angle of the centre of mass of the combined bike + rider.";
CM_ SG_ 2304154658 GPS_Lateral_Accel "GPS-derived lateral acceleration.  This is derived by differentiating GPS heading - it is much more noisy than lateral accel from the accelerometers, but useful for m/cycle applications.";
CM_ SG_ 2304154658 Accuracy_GPS_Lateral_Accel "This accuracy value applies to both GPS-derived lateral acceleration and motorcycle lean angle, since both are derived from the rate of change of GPS heading.";
CM_ SG_ 2304154658 Validity_GPS_Mcycle_Lean "Valid when bit is set, invalid when bit is clear.";
CM_ SG_ 2304154658 Validity_GPS_Lateral_Accel "Valid when bit is set, invalid when bit is clear.";
CM_ SG_ 2304142370 GPS_nSv_RTK "Number of common satellites available to RTK solution";
CM_ SG_ 2304142370 GPS_nSv_2 "Number of satellites used in GPS solution by module 2 on RTK units.";
CM_ SG_ 2304142370 GPS_nSv "Number of satellites used in GPS solution";
CM_ SG_ 2304143650 GPS_Pos_ECEF_Z "ECEF Z position.  The ECEF Z axis originates from the Earth centre, and the positive Z axis intersects the Earth surface at the North Pole.";
CM_ SG_ 2304143650 GPS_Pos_ECEF_Y "ECEF Y position.  The ECEF Y axis originates from the Earth centre, and the positive Y axis intersects the Earth surface at zero degrees latittude and 90 degrees longitude.";
CM_ SG_ 2304143394 GPS_Pos_ECEF_X "ECEF X position.  The ECEF X axis originates from the Earth centre, and the positive X axis intersects the Earth surface at zero degrees latittude and zero degrees longitude (the intersection of the equator and the prime meridian).";
CM_ SG_ 2304143394 Accuracy_GPS_Pos_ECEF_Z "Dimensionless.  Lower values imply but do not guarantee better accuracy than higher values.";
CM_ SG_ 2304143394 Accuracy_GPS_Pos_ECEF_Y "Dimensionless.  Lower values imply but do not guarantee better accuracy than higher values.";
CM_ SG_ 2304143394 Accuracy_GPS_Pos_ECEF_X "Dimensionless.  Lower values imply but do not guarantee better accuracy than higher values.";
CM_ SG_ 2304143394 Validity_GPS_Pos_ECEF_Z "Valid when bit is set, invalid when bit is clear.";
CM_ SG_ 2304143394 Validity_GPS_Pos_ECEF_Y "Valid when bit is set, invalid when bit is clear.";
CM_ SG_ 2304143394 Validity_GPS_Pos_ECEF_X "Valid when bit is set, invalid when bit is clear.";
CM_ SG_ 2304142882 Accuracy_GPS_Pos_LLH_Altitude "This accuracy value applies to both 2D and 3D GPS speed.";
CM_ SG_ 2304142882 Accuracy_GPS_Pos_LLH_Longitude "This accuracy value applies to both 2D and 3D GPS speed.";
CM_ SG_ 2304142882 Accuracy_GPS_Pos_LLH_Latitude "This accuracy value applies to both 2D and 3D GPS speed.";
CM_ SG_ 2304142882 Validity_GPS_Pos_LLH_Altitude "Valid when bit is set, invalid when bit is clear.";
CM_ SG_ 2304142882 Validity_GPS_Pos_LLH_Longitude "Valid when bit is set, invalid when bit is clear.";
CM_ SG_ 2304142882 Validity_GPS_Pos_LLH_Latitude "Valid when bit is set, invalid when bit is clear.";
CM_ SG_ 2304147746 GPS_Gradient "This is GPS gradient, i.e. the vertical direction that the vehicle is travelling, NOT pointing (pitch).";
CM_ SG_ 2304147746 Accuracy_GPS_Gradient "Dimensionless.  Lower values imply but do not guarantee better accuracy than higher values.";
CM_ SG_ 2304147746 GPS_Heading "This is GPS heading, the direction that the vehicle is travelling in the local horizontal plane.";
CM_ SG_ 2304147746 Accuracy_GPS_Heading "Dimensionless.  Lower values imply but do not guarantee better accuracy than higher values.";
CM_ SG_ 2304147746 Validity_GPS_Gradient "Valid when bit is set, invalid when bit is clear.";
CM_ SG_ 2304147746 Validity_GPS_Heading "Valid when bit is set, invalid when bit is clear.";
CM_ SG_ 2304147490 GPS_Vel_ECEF_Z "ECEF Z velocity.  The ECEF Z axis originates from the Earth centre, and the positive Z axis intersects the Earth surface at the North Pole.";
CM_ SG_ 2304147490 GPS_Vel_ECEF_Y "ECEF Y velocity.  The ECEF Y axis originates from the Earth centre, and the positive Y axis intersects the Earth surface at zero degrees latittude and 90 degrees longitude.";
CM_ SG_ 2304147490 Validity_GPS_Vel_ECEF_Z "Valid when bit is set, invalid when bit is clear.";
CM_ SG_ 2304147490 Validity_GPS_Vel_ECEF_Y "Valid when bit is set, invalid when bit is clear.";
CM_ SG_ 2304147234 GPS_Vel_ECEF_X "ECEF X velocity.  The ECEF X axis originates from the Earth centre, and the positive X axis intersects the Earth surface at zero degrees latittude and zero degrees longitude (the intersection of the equator and the prime meridian).";
CM_ SG_ 2304147234 Validity_GPS_Vel_ECEF_X "Valid when bit is set, invalid when bit is clear.";
CM_ SG_ 2304146978 GPS_Vel_NED_D "VELNED D velocity.  This is the velocity vector directly downwards towards the Earth centre at the current local Earth surface position.";
CM_ SG_ 2304146978 Validity_GPS_Vel_NED_D "Valid when bit is set, invalid when bit is clear.";
CM_ SG_ 2304146722 GPS_Vel_NED_E "VELNED E velocity.  This is the velocity vector directly East at the current local Earth surface position.";
CM_ SG_ 2304146722 GPS_Vel_NED_N "VELNED N velocity.  This is the velocity vector directly North at the current local Earth surface position.";
CM_ SG_ 2304146722 Validity_GPS_Vel_NED_E "Valid when bit is set, invalid when bit is clear.";
CM_ SG_ 2304146722 Validity_GPS_Vel_NED_N "Valid when bit is set, invalid when bit is clear.";
CM_ SG_ 2304146466 GPS_Speed_3D "This is GPS scalar 3D speed - scalar speed with the local Z axis component included.";
CM_ SG_ 2304146466 GPS_Speed_2D "This is GPS scalar 2D speed - scalar speed with no local Z axis component included.";
CM_ SG_ 2304146466 Accuracy_GPS_Speed "This accuracy value applies to both 2D and 3D GPS speed.";
CM_ SG_ 2304146466 Validity_GPS_Speed_3D "Valid when bit is set, invalid when bit is clear.";
CM_ SG_ 2304146466 Validity_GPS_Speed_2D "Valid when bit is set, invalid when bit is clear.";
CM_ SG_ 2304142626 GPS_Time "GPS time is the time in seconds since midnight GMT on Saturday night.";
CM_ SG_ 2304142626 Validity_GPS_Week "Valid when bit is set, invalid when bit is clear.";
CM_ SG_ 2304142626 Validity_GPS_Time "Valid when bit is set, invalid when bit is clear.";
CM_ SG_ 2303355938 Accel_Vertical "Vertical acceleration.  This is positive when the vehicle accelerates in an upwards direction, e.g. when travelling through a dip.";
CM_ SG_ 2303355938 Accel_Lateral "Lateral acceleration.  This is positive when the vehicle accelerates towards the right, e.g. when cornering around a right-hand bend.";
CM_ SG_ 2303355938 Accel_Longitudinal "Longitudinal acceleration.  This is positive when the vehicle accelerates in a forwards direction.";
CM_ SG_ 2303355938 Accuracy_Accel "Dimensionless.  Lower values imply but do not guarantee better accuracy than higher values.";
CM_ SG_ 2303355938 Validity_Accel_Vertical "Valid when bit is set, invalid when bit is clear.";
CM_ SG_ 2303355938 Validity_Accel_Lateral "Valid when bit is set, invalid when bit is clear.";
CM_ SG_ 2303355938 Validity_Accel_Longitudinal "Valid when bit is set, invalid when bit is clear.";
CM_ SG_ 2303356194 Gyro_Rate_Roll "Roll rate is positive for clockwise rotation when looking at the rear of the vehicle from behind the vehicle.";
CM_ SG_ 2303356194 Gyro_Rate_Pitch "Pitch rate is positive for clockwise rotation when looking at the left hand side of the vehicle from the left of the vehicle.";
CM_ SG_ 2303356194 Gyro_Rate_Yaw "Yaw rate is positive for clockwise rotation when looking down on the vehicle from above.";
CM_ SG_ 2303356194 Accuracy_Gyro_Rates "Dimensionless.  Lower values imply but do not guarantee better accuracy than higher values.";
CM_ SG_ 2303356194 Validity_Gyro_Rate_Roll "Valid when bit is set, invalid when bit is clear.";
CM_ SG_ 2303356194 Validity_Gyro_Rate_Pitch "Valid when bit is set, invalid when bit is clear.";
CM_ SG_ 2303356194 Validity_Gyro_Rate_Yaw "Valid when bit is set, invalid when bit is clear.";
BA_DEF_ SG_  "GenSigStartValue" INT -2147483648 2147483647;
BA_DEF_DEF_  "GenSigStartValue" 0;
BA_ "GenSigStartValue" SG_ 2303355937 Accel_Vertical 16120;
BA_ "GenSigStartValue" SG_ 2303355937 Accel_Lateral -30000;
BA_ "GenSigStartValue" SG_ 2303355937 Accel_Longitudinal 32767;
BA_ "GenSigStartValue" SG_ 2303355937 Accuracy_Accel 127;
BA_ "GenSigStartValue" SG_ 2303355937 Validity_Accel_Lateral 1;
VAL_ 2304273442 INS_Status 2 "Converged" 1 "Initialised" 0 "Uninitialised" ;
VAL_ 2304273698 Validity_Roll 1 "Valid" 0 "Invalid" ;
VAL_ 2304273698 Validity_Pitch 1 "Valid" 0 "Invalid" ;
VAL_ 2304273698 Validity_Yaw 1 "Valid" 0 "Invalid" ;
VAL_ 2304208162 Status_Trigger 1 "Active" 0 "Inactive" ;
VAL_ 2304208162 Status_Serial_Output_2 1 "Active" 0 "Inactive" ;
VAL_ 2304208162 Status_Serial_Output_1 1 "Active" 0 "Inactive" ;
VAL_ 2304208162 Status_Pulse_Output 1 "Active" 0 "Inactive" ;
VAL_ 2304208162 Status_Analogue_4 1 "Active" 0 "Inactive" ;
VAL_ 2304208162 Status_Analogue_3 1 "Active" 0 "Inactive" ;
VAL_ 2304208162 Status_Analogue_2 1 "Active" 0 "Inactive" ;
VAL_ 2304208162 Status_Analogue_1 1 "Active" 0 "Inactive" ;
VAL_ 2304207906 Trigger_Timestamp_Type 1 "Rising edge" 0 "Falling edge" ;
VAL_ 2304142370 RTK_Status 4 "Multiple RTK solutions found" 3 "RTK solution OK" 2 "RTK solution failed" 1 "Not enough common satellites" 0 "Not attempting RTK solution" ;
VAL_ 2304142370 GPS_Status 12 "Lock: Carrier speed and position" 11 "Lock: Doppler speed and position" 10 "Lock: Position but no speed" 9 "Unused" 8 "Unused" 7 "Unused" 6 "Unused" 5 "Exceeded max. speed or alt." 4 "Solution failed" 3 "Solution aborted" 2 "Insufficient satellites" 1 "Searching for satellites" 0 "GPS module not detected" ;
